VERSION "..\..\trunk\components\winTestMT\code\canApi\dbcFiles\canBus_03.dbc, created by Octave and generateRandomDbc.m on 21-Feb-2017"

NS_ :

BS_:

BU_: ECU

BO_ 1519 frame_1519: 4 Vector__XXX
  SG_ checksum_1_8 : 0|8@1+ (1.0,0.0) [0.0|255.0] "" ECU
  SG_ sig_14_12 : 14|12@1+ (1.0000000000000005E-4,0.31622776601683794) [0.31622776601683794|0.7256277660168382] "A" ECU
  SG_ sig_8_6 : 8|6@1- (1.0,0.0) [-32.0|30.0] "" ECU
  SG_ sig_27_5 : 27|5@1+ (1.0000000000000006E-5,3.1622776601683794E-4) [3.1622776601683794E-4|6.162277660168381E-4] "km/h" ECU
  SG_ sig_26_1 : 26|1@1+ (1.0,0.0) [0.0|1.0] "" ECU

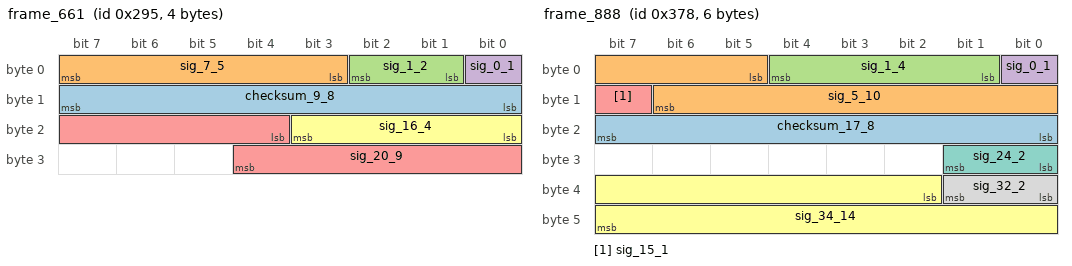
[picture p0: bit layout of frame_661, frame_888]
BO_ 661 frame_661: 4 ECU
  SG_ checksum_9_8 : 8|8@1+ (1.0,0.0) [0.0|255.0] "" Vector__XXX
  SG_ sig_7_5 : 7|5@0- (0.0010000000000000002,0.03162277660168379) [0.015622776601683788|0.0456227766016838] "km/h" Vector__XXX
  SG_ sig_1_2 : 1|2@1+ (1.0,0.0) [0.0|3.0] "" Vector__XXX
  SG_ sig_0_1 : 0|1@1+ (1.0,0.0) [0.0|1.0] "" Vector__XXX
  SG_ sig_20_9 : 20|9@1+ (1.0000000000000006E-6,3.1622776601683794E-4) [3.1622776601683794E-4|8.262277660168382E-4] "km/h" Vector__XXX
  SG_ sig_16_4 : 16|4@1+ (1.0,0.0) [0.0|14.0] "" Vector__XXX

BO_ 1084 frame_1084: 4 ECU
  SG_ checksum_1_8 : 0|8@1+ (1.0,0.0) [0.0|255.0] "" Vector__XXX
  SG_ sig_11_14 : 11|14@0+ (1.0000000000000009E-9,-3.162277660168379E-6) [-3.162277660168379E-6|1.3219722339831634E-5] "V" Vector__XXX
  SG_ sig_15_4 : 15|4@0- (1.0000000000000006E-5,-3.1622776601683795E-5) [-1.1162277660168384E-4|2.837722339831624E-5] "kWh" Vector__XXX

BO_ 888 frame_888: 6 Vector__XXX
  SG_ checksum_17_8 : 16|8@1+ (1.0,0.0) [0.0|255.0] "" ECU
  SG_ sig_5_10 : 5|10@1+ (1.0,0.0) [0.0|1022.0] "" ECU
  SG_ sig_1_4 : 1|4@1- (1.0,0.0) [-8.0|6.0] "" ECU
  SG_ sig_0_1 : 0|1@1+ (1.0,0.0) [0.0|1.0] "" ECU
  SG_ sig_15_1 : 15|1@1+ (1.0,0.0) [0.0|1.0] "" ECU
  SG_ sig_34_14 : 34|14@1- (1.0000000000000009E-9,-3.162277660168379E-6) [-1.1354277660168386E-5|5.027722339831629E-6] "A" ECU
  SG_ sig_24_2 : 24|2@1+ (1.0,0.0) [0.0|3.0] "" ECU
  SG_ sig_32_2 : 32|2@1+ (1.0,0.0) [0.0|3.0] "" ECU

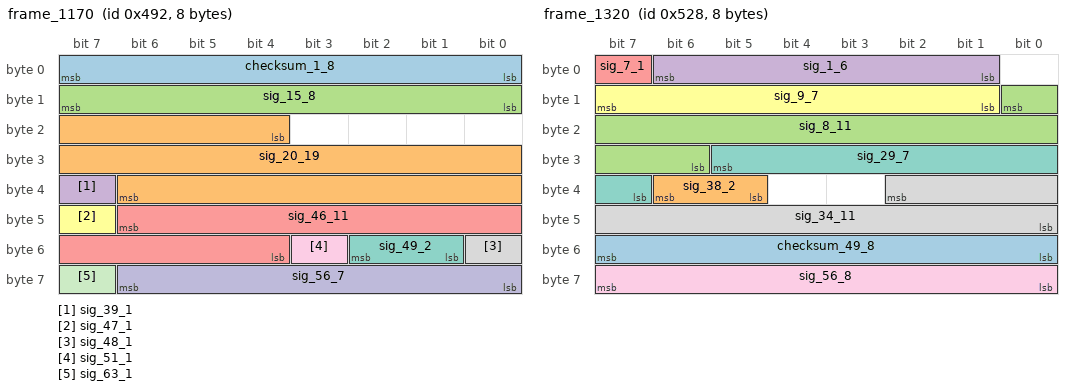
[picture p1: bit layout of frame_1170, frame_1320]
BO_ 1170 frame_1170: 8 ECU
  SG_ checksum_1_8 : 7|8@0+ (1.0,0.0) [0.0|255.0] "" Vector__XXX
  SG_ sig_20_19 : 20|19@1- (0.1,-31622.776601683792) [-57837.176601683794|-5408.5766016837915] "kWh" Vector__XXX
  SG_ sig_15_8 : 15|8@0+ (0.0010000000000000002,0.0) [0.0|0.25400000000000006] "V" Vector__XXX
  SG_ sig_39_1 : 39|1@0+ (1.0,0.0) [0.0|1.0] "" Vector__XXX
  SG_ sig_46_11 : 46|11@0+ (0.0010000000000000002,0.31622776601683794) [0.31622776601683794|2.3622277660168387] "V" Vector__XXX
  SG_ sig_47_1 : 47|1@0+ (1.0,0.0) [0.0|1.0] "" Vector__XXX
  SG_ sig_49_2 : 49|2@1- (1.0,0.0) [-2.0|1.0] "" Vector__XXX
  SG_ sig_48_1 : 48|1@1+ (1.0,0.0) [0.0|1.0] "" Vector__XXX
  SG_ sig_51_1 : 51|1@0+ (1.0,0.0) [0.0|1.0] "" Vector__XXX
  SG_ sig_56_7 : 56|7@1- (1.0000000000000007E-7,3.162277660168379E-6) [-3.2377223398316256E-6|9.362277660168384E-6] "km/h" Vector__XXX
  SG_ sig_63_1 : 63|1@1+ (1.0,0.0) [0.0|1.0] "" Vector__XXX

BO_ 1320 frame_1320: 8 Vector__XXX
  SG_ checksum_49_8 : 48|8@1+ (1.0,0.0) [0.0|255.0] "" ECU
  SG_ sig_38_2 : 38|2@0- (1.0,0.0) [-2.0|1.0] "" ECU
  SG_ sig_8_11 : 8|11@0+ (1.0,0.0) [0.0|2046.0] "" ECU
  SG_ sig_1_6 : 1|6@1- (1.0,0.0) [-32.0|30.0] "" ECU
  SG_ sig_7_1 : 7|1@0+ (1.0,0.0) [0.0|1.0] "" ECU
  SG_ sig_9_7 : 9|7@1- (0.010000000000000002,-0.31622776601683794) [-0.9562277660168381|0.30377223398316217] "s" ECU
  SG_ sig_29_7 : 29|7@0+ (10.0,0.0) [0.0|1260.0] "W" ECU
  SG_ sig_34_11 : 34|11@0+ (1.0,0.0) [0.0|2046.0] "" ECU
  SG_ sig_56_8 : 56|8@1+ (100.0,3162.2776601683795) [3162.2776601683795|28562.27766016838] "m/s^2" ECU

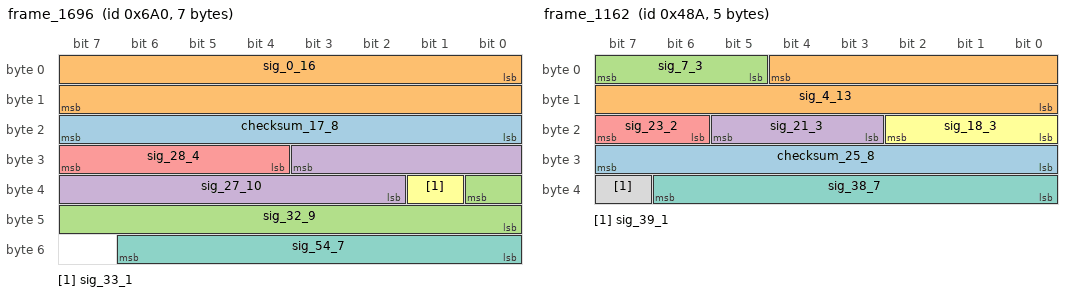
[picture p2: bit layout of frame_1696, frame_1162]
BO_ 1696 frame_1696: 7 ECU
  SG_ checksum_17_8 : 16|8@1+ (1.0,0.0) [0.0|255.0] "" Vector__XXX
  SG_ sig_0_16 : 0|16@1+ (1.0000000000000009E-9,3.1622776601683795E-5) [3.1622776601683795E-5|9.715677660168386E-5] "s" Vector__XXX
  SG_ sig_32_9 : 32|9@0- (1.0,0.0) [-256.0|254.0] "" Vector__XXX
  SG_ sig_27_10 : 27|10@0- (0.1,31.622776601683793) [-19.57722339831621|82.6227766016838] "kWh" Vector__XXX
  SG_ sig_28_4 : 28|4@1- (1.0,0.0) [-8.0|6.0] "" Vector__XXX
  SG_ sig_33_1 : 33|1@1+ (1.0,0.0) [0.0|1.0] "" Vector__XXX
  SG_ sig_54_7 : 54|7@0- (1.0000000000000006E-5,3.1622776601683794E-4) [-3.2377223398316244E-4|9.362277660168383E-4] "A" Vector__XXX

BO_ 1162 frame_1162: 5 Vector__XXX
  SG_ checksum_25_8 : 31|8@0+ (1.0,0.0) [0.0|255.0] "" ECU
  SG_ sig_4_13 : 4|13@0- (1.0000000000000005E-4,0.31622776601683794) [-0.09337223398316224|0.7256277660168382] "V" ECU
  SG_ sig_7_3 : 7|3@0- (1.0,0.0) [-4.0|2.0] "" ECU
  SG_ sig_21_3 : 21|3@0+ (1.0,0.0) [0.0|6.0] "" ECU
  SG_ sig_23_2 : 23|2@0- (1.0,0.0) [-2.0|1.0] "" ECU
  SG_ sig_18_3 : 18|3@0- (1.0,0.0) [-4.0|2.0] "" ECU
  SG_ sig_38_7 : 38|7@0+ (10.0,-316.22776601683796) [-316.22776601683796|943.7722339831621] "kWh" ECU
  SG_ sig_39_1 : 39|1@0+ (1.0,0.0) [0.0|1.0] "" ECU

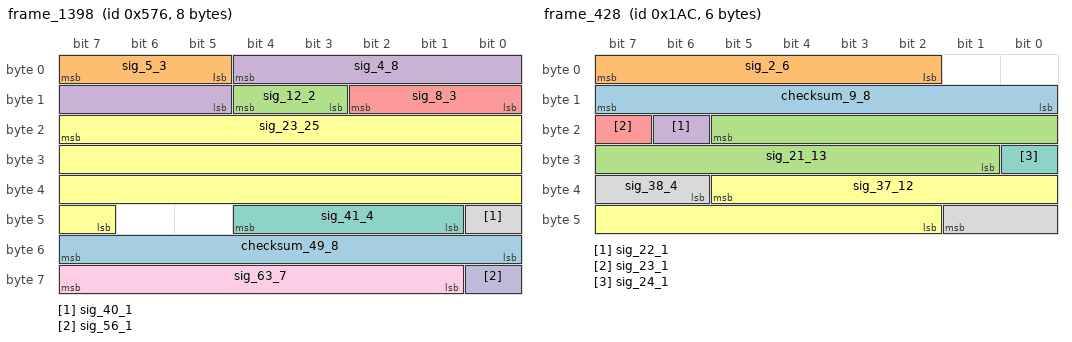
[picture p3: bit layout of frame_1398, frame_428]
BO_ 1398 frame_1398: 8 ECU
  SG_ checksum_49_8 : 55|8@0+ (1.0,0.0) [0.0|255.0] "" Vector__XXX
  SG_ sig_5_3 : 5|3@1- (1.0,0.0) [-4.0|2.0] "" Vector__XXX
  SG_ sig_12_2 : 12|2@0- (1.0,0.0) [-2.0|1.0] "" Vector__XXX
  SG_ sig_4_8 : 4|8@0- (1.0000000000000006E-6,-3.1622776601683795E-5) [-1.5962277660168386E-4|9.437722339831629E-5] "W" Vector__XXX
  SG_ sig_8_3 : 8|3@1- (1.0,0.0) [-4.0|2.0] "" Vector__XXX
  SG_ sig_23_25 : 23|25@0+ (1.0000000000000006E-5,316.22776601683796) [316.22776601683796|651.7720660168382] "km/h" Vector__XXX
  SG_ sig_41_4 : 41|4@1+ (1.0,0.0) [0.0|14.0] "" Vector__XXX
  SG_ sig_40_1 : 40|1@1+ (1.0,0.0) [0.0|1.0] "" Vector__XXX
  SG_ sig_63_7 : 63|7@0+ (1.0,0.0) [0.0|126.0] "" Vector__XXX
  SG_ sig_56_1 : 56|1@0+ (1.0,0.0) [0.0|1.0] "" Vector__XXX

BO_ 187 frame_187: 4 Vector__XXX
  SG_ checksum_1_8 : 0|8@1+ (1.0,0.0) [0.0|255.0] "" ECU
  SG_ sig_13_16 : 13|16@0+ (1.0,0.0) [0.0|65534.0] "" ECU
  SG_ sig_15_2 : 15|2@0- (1.0,0.0) [-2.0|1.0] "" ECU
  SG_ sig_28_5 : 28|5@0+ (1.0,0.0) [0.0|30.0] "" ECU

BO_ 428 frame_428: 6 Vector__XXX
  SG_ checksum_9_8 : 15|8@0+ (1.0,0.0) [0.0|255.0] "" ECU
  SG_ sig_2_6 : 2|6@1+ (0.010000000000000002,-0.31622776601683794) [-0.31622776601683794|0.30377223398316217] "A" ECU
  SG_ sig_21_13 : 21|13@0- (1.0,0.0) [-4096.0|4094.0] "" ECU
  SG_ sig_22_1 : 22|1@0+ (1.0,0.0) [0.0|1.0] "" ECU
  SG_ sig_23_1 : 23|1@0+ (1.0,0.0) [0.0|1.0] "" ECU
  SG_ sig_37_12 : 37|12@0- (0.1,316.22776601683796) [111.42776601683795|520.827766016838] "kWh" ECU
  SG_ sig_24_1 : 24|1@1+ (1.0,0.0) [0.0|1.0] "" ECU
  SG_ sig_38_4 : 38|4@1+ (0.0010000000000000002,0.0) [0.0|0.014000000000000004] "A" ECU

BO_ 1425 frame_1425: 5 ECU
  SG_ checksum_25_8 : 24|8@1+ (1.0,0.0) [0.0|255.0] "" Vector__XXX
  SG_ sig_7_16 : 7|16@1+ (1.0,0.0) [0.0|65534.0] "" Vector__XXX
  SG_ sig_6_7 : 6|7@0+ (1.0,0.0) [0.0|126.0] "" Vector__XXX
  SG_ sig_23_1 : 23|1@0+ (1.0,0.0) [0.0|1.0] "" Vector__XXX
  SG_ sig_39_8 : 39|8@0- (1.0,0.0) [-128.0|126.0] "" Vector__XXX

BO_ 1217 frame_1217: 3 Vector__XXX
  SG_ checksum_17_8 : 23|8@0+ (1.0,0.0) [0.0|255.0] "" ECU
  SG_ sig_4_10 : 4|10@0- (1.0,0.0) [-512.0|510.0] "" ECU
  SG_ sig_7_2 : 7|2@0+ (1.0,0.0) [0.0|3.0] "" ECU
  SG_ sig_5_1 : 5|1@0+ (1.0,0.0) [0.0|1.0] "" ECU
  SG_ sig_10_3 : 10|3@0+ (1.0,0.0) [0.0|6.0] "" ECU

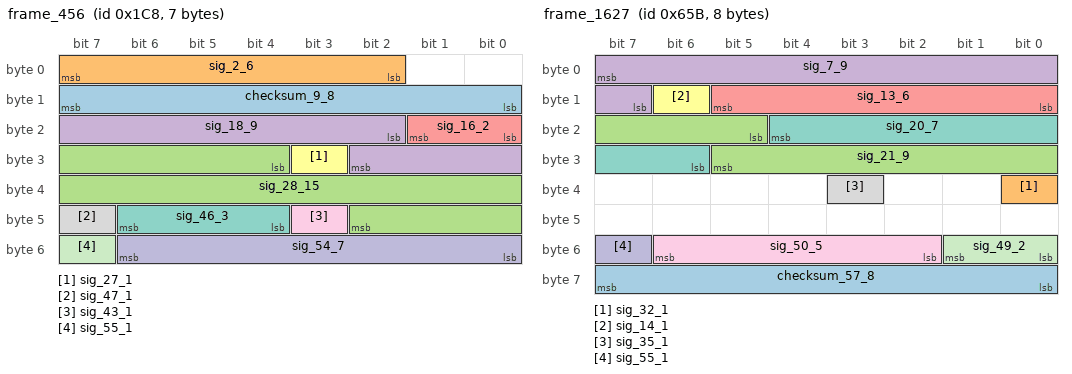
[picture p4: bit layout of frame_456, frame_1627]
BO_ 456 frame_456: 7 Vector__XXX
  SG_ checksum_9_8 : 8|8@1+ (1.0,0.0) [0.0|255.0] "" ECU
  SG_ sig_2_6 : 2|6@1+ (0.1,3.1622776601683795) [3.1622776601683795|9.36227766016838] "km/h" ECU
  SG_ sig_28_15 : 28|15@1- (0.1,3162.2776601683795) [1523.8776601683794|4800.47766016838] "V" ECU
  SG_ sig_18_9 : 18|9@1- (0.010000000000000002,0.0) [-2.5600000000000005|2.5400000000000005] "kWh" ECU
  SG_ sig_16_2 : 16|2@1+ (1.0,0.0) [0.0|3.0] "" ECU
  SG_ sig_27_1 : 27|1@1+ (1.0,0.0) [0.0|1.0] "" ECU
  SG_ sig_46_3 : 46|3@0- (1.0,0.0) [-4.0|2.0] "" ECU
  SG_ sig_47_1 : 47|1@0+ (1.0,0.0) [0.0|1.0] "" ECU
  SG_ sig_43_1 : 43|1@1+ (1.0,0.0) [0.0|1.0] "" ECU
  SG_ sig_54_7 : 54|7@0- (1.0,0.0) [-64.0|62.0] "" ECU
  SG_ sig_55_1 : 55|1@0+ (1.0,0.0) [0.0|1.0] "" ECU

BO_ 1627 frame_1627: 8 Vector__XXX
  SG_ checksum_57_8 : 56|8@1+ (1.0,0.0) [0.0|255.0] "" ECU
  SG_ sig_32_1 : 32|1@0+ (1.0,0.0) [0.0|1.0] "" ECU
  SG_ sig_21_9 : 21|9@1- (0.1,31.622776601683793) [6.022776601683791|57.022776601683795] "km/h" ECU
  SG_ sig_7_9 : 7|9@0- (0.010000000000000002,0.0) [-2.5600000000000005|2.5400000000000005] "m/s^2" ECU
  SG_ sig_13_6 : 13|6@0+ (1.0,0.0) [0.0|62.0] "" ECU
  SG_ sig_14_1 : 14|1@1+ (1.0,0.0) [0.0|1.0] "" ECU
  SG_ sig_20_7 : 20|7@0+ (1000.0,0.0) [0.0|126000.0] "kWh" ECU
  SG_ sig_35_1 : 35|1@1+ (1.0,0.0) [0.0|1.0] "" ECU
  SG_ sig_50_5 : 50|5@1+ (1.0000000000000005E-4,0.0) [0.0|0.0030000000000000014] "km/h" ECU
  SG_ sig_55_1 : 55|1@0+ (1.0,0.0) [0.0|1.0] "" ECU
  SG_ sig_49_2 : 49|2@0+ (1.0,0.0) [0.0|3.0] "" ECU

BO_ 804 frame_804: 7 Vector__XXX
  SG_ checksum_9_8 : 15|8@0+ (1.0,0.0) [0.0|255.0] "" ECU
  SG_ sig_7_7 : 7|7@0+ (0.0010000000000000002,0.03162277660168379) [0.03162277660168379|0.15762277660168383] "km/h" ECU
  SG_ sig_0_1 : 0|1@0+ (1.0,0.0) [0.0|1.0] "" ECU
  SG_ sig_22_19 : 22|19@0- (1.0000000000000011E-10,0.0) [-2.6214400000000028E-5|2.6214200000000028E-5] "kWh" ECU
  SG_ sig_34_19 : 34|19@0- (1.000000000000001E-11,-3.162277660168379E-6) [-5.783717660168382E-6|-5.408576601683765E-7] "V" ECU
  SG_ sig_35_1 : 35|1@0+ (1.0,0.0) [0.0|1.0] "" ECU

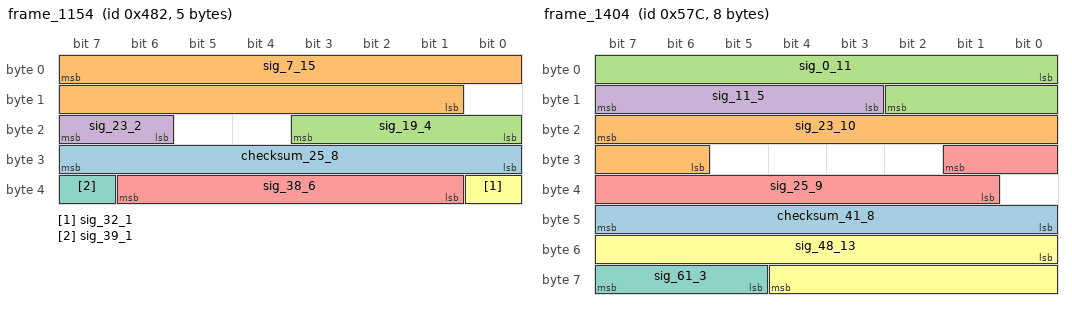
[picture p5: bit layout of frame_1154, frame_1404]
BO_ 1154 frame_1154: 5 ECU
  SG_ checksum_25_8 : 31|8@0+ (1.0,0.0) [0.0|255.0] "" Vector__XXX
  SG_ sig_7_15 : 7|15@0+ (0.1,-3162.2776601683795) [-3162.2776601683795|114.32233983162087] "m/s^2" Vector__XXX
  SG_ sig_19_4 : 19|4@0- (1.0000000000000006E-5,0.0) [-8.000000000000005E-5|6.0000000000000035E-5] "km/h" Vector__XXX
  SG_ sig_23_2 : 23|2@0+ (1.0,0.0) [0.0|3.0] "" Vector__XXX
  SG_ sig_38_6 : 38|6@0- (1.0,0.0) [-32.0|30.0] "" Vector__XXX
  SG_ sig_32_1 : 32|1@1+ (1.0,0.0) [0.0|1.0] "" Vector__XXX
  SG_ sig_39_1 : 39|1@0+ (1.0,0.0) [0.0|1.0] "" Vector__XXX

BO_ 1404 frame_1404: 8 ECU
  SG_ checksum_41_8 : 47|8@0+ (1.0,0.0) [0.0|255.0] "" Vector__XXX
  SG_ sig_23_10 : 23|10@0+ (1.0000000000000005E-4,0.0) [0.0|0.10220000000000004] "kWh" Vector__XXX
  SG_ sig_0_11 : 0|11@1+ (1.0,0.0) [0.0|2046.0] "" Vector__XXX
  SG_ sig_11_5 : 11|5@1+ (100.0,3162.2776601683795) [3162.2776601683795|6162.27766016838] "W" Vector__XXX
  SG_ sig_25_9 : 25|9@0- (0.010000000000000002,3.1622776601683795) [0.602277660168379|5.70227766016838] "m/s^2" Vector__XXX
  SG_ sig_48_13 : 48|13@1+ (1.0000000000000006E-5,0.0) [0.0|0.08190000000000004] "W" Vector__XXX
  SG_ sig_61_3 : 61|3@1+ (1.0,0.0) [0.0|6.0] "" Vector__XXX

BO_ 259 frame_259: 4 Vector__XXX
  SG_ checksum_1_8 : 0|8@1+ (1.0,0.0) [0.0|255.0] "" ECU
  SG_ sig_13_17 : 13|17@1- (1.0000000000000006E-6,0.03162277660168379) [-0.03391322339831625|0.09715677660168383] "V" ECU
  SG_ sig_11_4 : 11|4@0- (100.0,316.22776601683796) [-483.77223398316204|916.2277660168379] "m/s^2" ECU

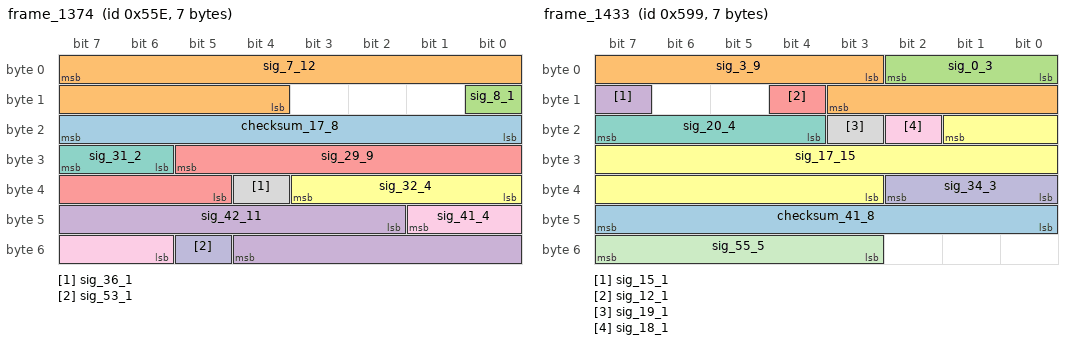
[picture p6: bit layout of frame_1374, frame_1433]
BO_ 1374 frame_1374: 7 ECU
  SG_ checksum_17_8 : 23|8@0+ (1.0,0.0) [0.0|255.0] "" Vector__XXX
  SG_ sig_7_12 : 7|12@0+ (1.0,0.0) [0.0|4094.0] "" Vector__XXX
  SG_ sig_8_1 : 8|1@1+ (1.0,0.0) [0.0|1.0] "" Vector__XXX
  SG_ sig_42_11 : 42|11@1- (1.0000000000000006E-6,3.1622776601683794E-4) [-7.077722339831627E-4|0.0013382277660168385] "kWh" Vector__XXX
  SG_ sig_29_9 : 29|9@0- (0.0010000000000000002,0.31622776601683794) [0.06022776601683788|0.570227766016838] "s" Vector__XXX
  SG_ sig_32_4 : 32|4@1- (1.0,0.0) [-8.0|6.0] "" Vector__XXX
  SG_ sig_31_2 : 31|2@0- (1.0,0.0) [-2.0|1.0] "" Vector__XXX
  SG_ sig_36_1 : 36|1@1+ (1.0,0.0) [0.0|1.0] "" Vector__XXX
  SG_ sig_41_4 : 41|4@0+ (0.0010000000000000002,-0.0031622776601683794) [-0.0031622776601683794|0.010837722339831624] "s" Vector__XXX
  SG_ sig_53_1 : 53|1@1+ (1.0,0.0) [0.0|1.0] "" Vector__XXX

BO_ 820 frame_820: 4 ECU
  SG_ checksum_25_8 : 31|8@0+ (1.0,0.0) [0.0|255.0] "" Vector__XXX
  SG_ sig_0_14 : 0|14@1- (1.0000000000000009E-9,3.162277660168379E-6) [-5.029722339831628E-6|1.1352277660168387E-5] "kWh" Vector__XXX
  SG_ sig_17_5 : 17|5@1+ (1.0,-31.622776601683793) [-31.622776601683793|-1.6227766016837926] "V" Vector__XXX
  SG_ sig_23_1 : 23|1@0+ (1.0,0.0) [0.0|1.0] "" Vector__XXX
  SG_ sig_22_1 : 22|1@0+ (1.0,0.0) [0.0|1.0] "" Vector__XXX
  SG_ sig_16_1 : 16|1@0+ (1.0,0.0) [0.0|1.0] "" Vector__XXX

BO_ 1433 frame_1433: 7 Vector__XXX
  SG_ checksum_41_8 : 40|8@1+ (1.0,0.0) [0.0|255.0] "" ECU
  SG_ sig_3_9 : 3|9@1+ (1.0,0.0) [0.0|510.0] "" ECU
  SG_ sig_0_3 : 0|3@1+ (1.0,0.0) [0.0|6.0] "" ECU
  SG_ sig_15_1 : 15|1@0+ (1.0,0.0) [0.0|1.0] "" ECU
  SG_ sig_12_1 : 12|1@1+ (1.0,0.0) [0.0|1.0] "" ECU
  SG_ sig_17_15 : 17|15@0+ (1.0000000000000006E-6,0.03162277660168379) [0.03162277660168379|0.06438877660168381] "kWh" ECU
  SG_ sig_20_4 : 20|4@1- (10000.0,0.0) [-80000.0|60000.0] "s" ECU
  SG_ sig_19_1 : 19|1@0+ (1.0,0.0) [0.0|1.0] "" ECU
  SG_ sig_18_1 : 18|1@1+ (1.0,0.0) [0.0|1.0] "" ECU
  SG_ sig_34_3 : 34|3@0+ (1.0,0.0) [0.0|6.0] "" ECU
  SG_ sig_55_5 : 55|5@0- (100.0,3162.2776601683795) [1562.2776601683795|4562.27766016838] "m/s^2" ECU

BO_ 1820 frame_1820: 4 Vector__XXX
  SG_ checksum_25_8 : 31|8@0+ (1.0,0.0) [0.0|255.0] "" ECU
  SG_ sig_2_16 : 2|16@0+ (1.0,0.0) [0.0|65534.0] "" ECU
  SG_ sig_7_4 : 7|4@0- (10.0,0.0) [-80.0|60.0] "kWh" ECU
  SG_ sig_17_2 : 17|2@1+ (1.0,0.0) [0.0|3.0] "" ECU

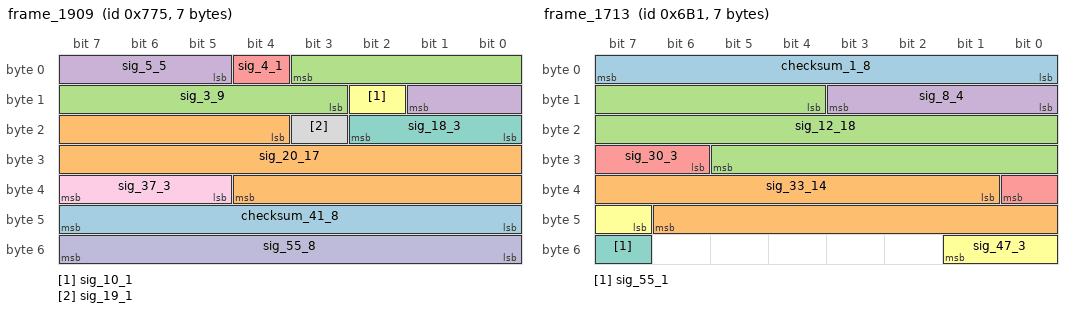
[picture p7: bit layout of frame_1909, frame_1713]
BO_ 1909 frame_1909: 7 Vector__XXX
  SG_ checksum_41_8 : 47|8@0+ (1.0,0.0) [0.0|255.0] "" ECU
  SG_ sig_20_17 : 20|17@1- (1.0,0.0) [-65536.0|65534.0] "" ECU
  SG_ sig_3_9 : 3|9@0+ (0.1,-31.622776601683793) [-31.622776601683793|19.377223398316207] "s" ECU
  SG_ sig_5_5 : 5|5@1+ (1.0,0.0) [0.0|30.0] "" ECU
  SG_ sig_4_1 : 4|1@0+ (1.0,0.0) [0.0|1.0] "" ECU
  SG_ sig_10_1 : 10|1@0+ (1.0,0.0) [0.0|1.0] "" ECU
  SG_ sig_18_3 : 18|3@0+ (1.0,0.0) [0.0|6.0] "" ECU
  SG_ sig_19_1 : 19|1@0+ (1.0,0.0) [0.0|1.0] "" ECU
  SG_ sig_37_3 : 37|3@1+ (1.0,0.0) [0.0|6.0] "" ECU
  SG_ sig_55_8 : 55|8@0- (10.0,316.22776601683796) [-963.7722339831621|1576.227766016838] "km/h" ECU

BO_ 1713 frame_1713: 7 ECU
  SG_ checksum_1_8 : 0|8@1+ (1.0,0.0) [0.0|255.0] "" Vector__XXX
  SG_ sig_33_14 : 33|14@1+ (1.0,0.0) [0.0|16382.0] "" Vector__XXX
  SG_ sig_12_18 : 12|18@1+ (1.0,0.0) [0.0|262142.0] "" Vector__XXX
  SG_ sig_8_4 : 8|4@1+ (1.0000000000000005E-4,-3.1622776601683794E-4) [-3.1622776601683794E-4|0.0010837722339831627] "kWh" Vector__XXX
  SG_ sig_30_3 : 30|3@1- (1.0,0.0) [-4.0|2.0] "" Vector__XXX
  SG_ sig_47_3 : 47|3@1+ (1.0,0.0) [0.0|6.0] "" Vector__XXX
  SG_ sig_55_1 : 55|1@0+ (1.0,0.0) [0.0|1.0] "" Vector__XXX

BO_ 1318 frame_1318: 5 Vector__XXX
  SG_ checksum_9_8 : 15|8@0+ (1.0,0.0) [0.0|255.0] "" ECU
  SG_ sig_5_5 : 5|5@0- (10.0,0.0) [-160.0|140.0] "W" ECU
  SG_ sig_7_2 : 7|2@0- (1.0,0.0) [-2.0|1.0] "" ECU
  SG_ sig_31_16 : 31|16@0+ (0.1,0.0) [0.0|6553.400000000001] "s" ECU
  SG_ sig_22_7 : 22|7@0- (1.0,0.0) [-64.0|62.0] "" ECU
  SG_ sig_23_1 : 23|1@0+ (1.0,0.0) [0.0|1.0] "" ECU

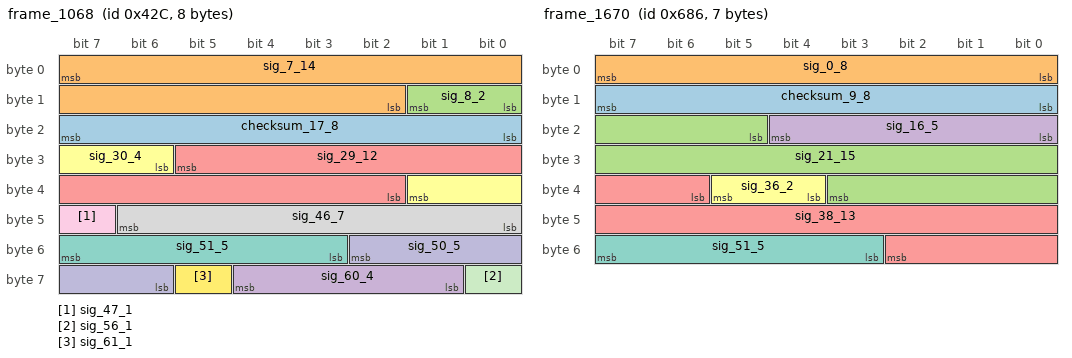
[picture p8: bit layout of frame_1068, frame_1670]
BO_ 1068 frame_1068: 8 Vector__XXX
  SG_ checksum_17_8 : 23|8@0+ (1.0,0.0) [0.0|255.0] "" ECU
  SG_ sig_7_14 : 7|14@0- (1.0000000000000005E-4,-0.31622776601683794) [-1.1354277660168384|0.5027722339831624] "s" ECU
  SG_ sig_8_2 : 8|2@1- (1.0,0.0) [-2.0|1.0] "" ECU
  SG_ sig_60_4 : 60|4@0+ (0.0010000000000000002,-0.0031622776601683794) [-0.0031622776601683794|0.010837722339831624] "km/h" ECU
  SG_ sig_29_12 : 29|12@0+ (1.0000000000000006E-6,0.0031622776601683794) [0.0031622776601683794|0.007256277660168382] "s" ECU
  SG_ sig_30_4 : 30|4@1- (1.0,0.0) [-8.0|6.0] "" ECU
  SG_ sig_51_5 : 51|5@1+ (1000.0,0.0) [0.0|30000.0] "V" ECU
  SG_ sig_46_7 : 46|7@0+ (1.0000000000000006E-6,3.1622776601683795E-5) [3.1622776601683795E-5|1.5762277660168387E-4] "km/h" ECU
  SG_ sig_47_1 : 47|1@0+ (1.0,0.0) [0.0|1.0] "" ECU
  SG_ sig_50_5 : 50|5@0- (0.1,0.0) [-1.6|1.4000000000000001] "m/s^2" ECU
  SG_ sig_56_1 : 56|1@1+ (1.0,0.0) [0.0|1.0] "" ECU
  SG_ sig_61_1 : 61|1@1+ (1.0,0.0) [0.0|1.0] "" ECU

BO_ 1670 frame_1670: 7 Vector__XXX
  SG_ checksum_9_8 : 8|8@1+ (1.0,0.0) [0.0|255.0] "" ECU
  SG_ sig_0_8 : 0|8@1- (1000.0,0.0) [-128000.0|126000.0] "s" ECU
  SG_ sig_21_15 : 21|15@1+ (1.0,0.0) [0.0|32766.0] "" ECU
  SG_ sig_16_5 : 16|5@1+ (0.1,-3.1622776601683795) [-3.1622776601683795|-0.16227766016837952] "W" ECU
  SG_ sig_38_13 : 38|13@1+ (1.0,-3162.2776601683795) [-3162.2776601683795|5027.72233983162] "kWh" ECU
  SG_ sig_36_2 : 36|2@1- (1.0,0.0) [-2.0|1.0] "" ECU
  SG_ sig_51_5 : 51|5@1+ (1.0,0.0) [0.0|30.0] "" ECU

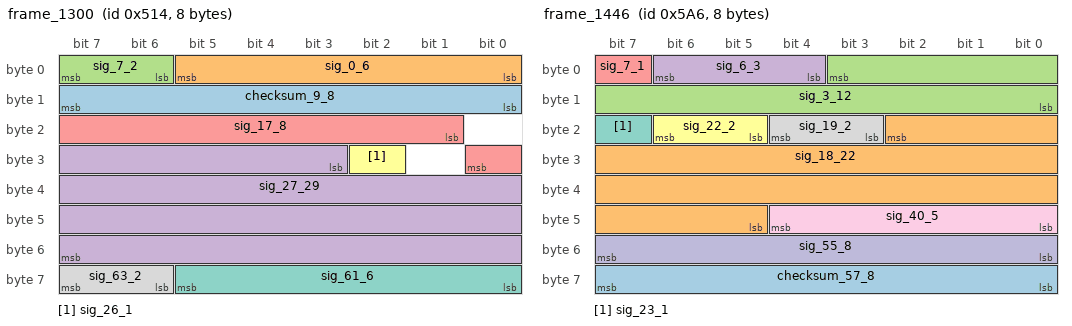
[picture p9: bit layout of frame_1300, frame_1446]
BO_ 1300 frame_1300: 8 Vector__XXX
  SG_ checksum_9_8 : 15|8@0+ (1.0,0.0) [0.0|255.0] "" ECU
  SG_ sig_0_6 : 0|6@1- (1000.0,-31622.776601683792) [-63622.77660168379|-1622.7766016837923] "s" ECU
  SG_ sig_7_2 : 7|2@0- (1.0,0.0) [-2.0|1.0] "" ECU
  SG_ sig_27_29 : 27|29@1- (1.0000000000000011E-10,-0.03162277660168379) [-0.058466322201683824|-0.004779231201683762] "A" ECU
  SG_ sig_17_8 : 17|8@1+ (0.1,3.1622776601683795) [3.1622776601683795|28.56227766016838] "W" ECU
  SG_ sig_26_1 : 26|1@0+ (1.0,0.0) [0.0|1.0] "" ECU
  SG_ sig_61_6 : 61|6@0- (1.0000000000000005E-4,-0.0031622776601683794) [-0.006362277660168381|-1.6227766016837803E-4] "m/s^2" ECU
  SG_ sig_63_2 : 63|2@0- (1.0,0.0) [-2.0|1.0] "" ECU

BO_ 1446 frame_1446: 8 Vector__XXX
  SG_ checksum_57_8 : 63|8@0+ (1.0,0.0) [0.0|255.0] "" ECU
  SG_ sig_18_22 : 18|22@0- (1.0000000000000007E-7,-0.31622776601683794) [-0.5259429660168381|-0.10651276601683779] "W" ECU
  SG_ sig_3_12 : 3|12@0- (1.0000000000000007E-7,-3.1622776601683794E-4) [-5.210277660168381E-4|-1.1162776601683779E-4] "A" ECU
  SG_ sig_6_3 : 6|3@0+ (1.0,0.0) [0.0|6.0] "" ECU
  SG_ sig_7_1 : 7|1@1+ (1.0,0.0) [0.0|1.0] "" ECU
  SG_ sig_22_2 : 22|2@0+ (1.0,0.0) [0.0|3.0] "" ECU
  SG_ sig_23_1 : 23|1@0+ (1.0,0.0) [0.0|1.0] "" ECU
  SG_ sig_19_2 : 19|2@1+ (1.0,0.0) [0.0|3.0] "" ECU
  SG_ sig_40_5 : 40|5@1+ (1.0,0.0) [0.0|30.0] "" ECU
  SG_ sig_55_8 : 55|8@0+ (0.010000000000000002,0.0) [0.0|2.5400000000000005] "km/h" ECU

BO_ 144 frame_144: 6 Vector__XXX
  SG_ checksum_25_8 : 24|8@1+ (1.0,0.0) [0.0|255.0] "" ECU
  SG_ sig_3_17 : 3|17@1- (1.0000000000000005E-4,3.1622776601683795) [-3.3913223398316235|9.715677660168382] "V" ECU
  SG_ sig_0_3 : 0|3@1+ (1.0,0.0) [0.0|6.0] "" ECU
  SG_ sig_20_4 : 20|4@1- (1.0,-3.1622776601683795) [-11.16227766016838|2.8377223398316205] "s" ECU
  SG_ sig_32_11 : 32|11@1+ (1.0000000000000008E-8,3.162277660168379E-6) [3.162277660168379E-6|2.3622277660168395E-5] "s" ECU
  SG_ sig_43_5 : 43|5@1+ (1.0,0.0) [0.0|30.0] "" ECU

BO_ 1029 frame_1029: 7 Vector__XXX
  SG_ checksum_9_8 : 15|8@0+ (1.0,0.0) [0.0|255.0] "" ECU
  SG_ sig_7_6 : 7|6@0- (1.0,0.0) [-32.0|30.0] "" ECU
  SG_ sig_1_2 : 1|2@0- (1.0,0.0) [-2.0|1.0] "" ECU
  SG_ sig_16_33 : 16|33@1+ (1.000000000000001E-11,0.03162277660168379) [0.03162277660168379|0.11752212250168388] "V" ECU
  SG_ sig_50_2 : 50|2@0+ (1.0,0.0) [0.0|3.0] "" ECU

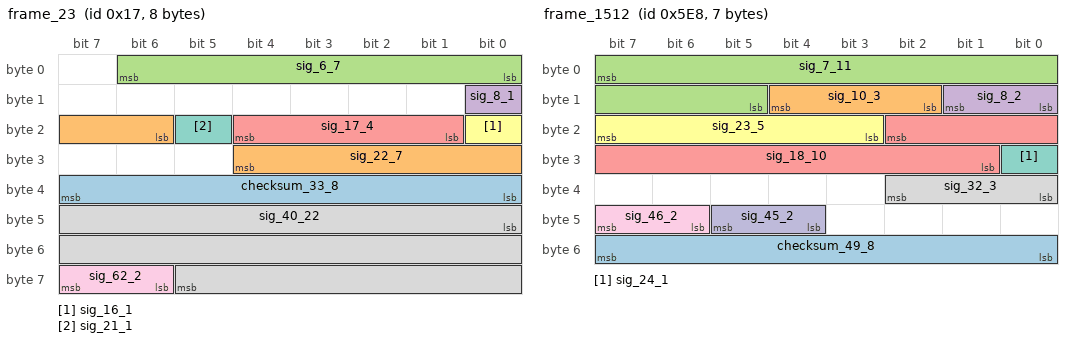
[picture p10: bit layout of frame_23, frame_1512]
BO_ 23 frame_23: 8 Vector__XXX
  SG_ checksum_33_8 : 32|8@1+ (1.0,0.0) [0.0|255.0] "" ECU
  SG_ sig_22_7 : 22|7@1- (0.010000000000000002,0.31622776601683794) [-0.3237722339831622|0.9362277660168381] "km/h" ECU
  SG_ sig_6_7 : 6|7@0+ (0.1,-3.1622776601683795) [-3.1622776601683795|9.437722339831621] "s" ECU
  SG_ sig_8_1 : 8|1@1+ (1.0,0.0) [0.0|1.0] "" ECU
  SG_ sig_17_4 : 17|4@1- (0.010000000000000002,0.0) [-0.08000000000000002|0.06000000000000001] "W" ECU
  SG_ sig_16_1 : 16|1@1+ (1.0,0.0) [0.0|1.0] "" ECU
  SG_ sig_21_1 : 21|1@0+ (1.0,0.0) [0.0|1.0] "" ECU
  SG_ sig_40_22 : 40|22@1- (1.0000000000000005E-4,0.0) [-209.7152000000001|209.7150000000001] "km/h" ECU
  SG_ sig_62_2 : 62|2@1+ (1.0,0.0) [0.0|3.0] "" ECU

BO_ 1485 frame_1485: 7 ECU
  SG_ checksum_49_8 : 55|8@0+ (1.0,0.0) [0.0|255.0] "" Vector__XXX
  SG_ sig_11_20 : 11|20@0+ (1.0000000000000005E-4,-31.622776601683793) [-31.622776601683793|73.23462339831624] "m/s^2" Vector__XXX
  SG_ sig_7_12 : 7|12@0- (10.0,-31622.776601683792) [-52102.77660168379|-11162.776601683792] "V" Vector__XXX
  SG_ sig_39_11 : 39|11@0- (1.0000000000000006E-5,0.0) [-0.010240000000000006|0.010220000000000007] "kWh" Vector__XXX
  SG_ sig_42_3 : 42|3@0- (1.0,0.0) [-4.0|2.0] "" Vector__XXX
  SG_ sig_44_2 : 44|2@0+ (1.0,0.0) [0.0|3.0] "" Vector__XXX

BO_ 1262 frame_1262: 5 Vector__XXX
  SG_ checksum_33_8 : 32|8@1+ (1.0,0.0) [0.0|255.0] "" ECU
  SG_ sig_7_21 : 7|21@1- (1.0000000000000011E-10,3.1622776601683795E-5) [-7.323482339831631E-5|1.364801766016839E-4] "A" ECU
  SG_ sig_6_7 : 6|7@0+ (1.0,0.0) [0.0|126.0] "" ECU
  SG_ sig_31_4 : 31|4@0- (0.010000000000000002,0.03162277660168379) [-0.048377223398316224|0.0916227766016838] "W" ECU

BO_ 1512 frame_1512: 7 Vector__XXX
  SG_ checksum_49_8 : 48|8@1+ (1.0,0.0) [0.0|255.0] "" ECU
  SG_ sig_10_3 : 10|3@1- (1.0,0.0) [-4.0|2.0] "" ECU
  SG_ sig_7_11 : 7|11@0+ (1.0,0.0) [0.0|2046.0] "" ECU
  SG_ sig_8_2 : 8|2@1+ (1.0,0.0) [0.0|3.0] "" ECU
  SG_ sig_18_10 : 18|10@0+ (0.1,-31.622776601683793) [-31.622776601683793|70.5772233983162] "V" ECU
  SG_ sig_23_5 : 23|5@0+ (1.0000000000000006E-5,0.0) [0.0|3.000000000000002E-4] "kWh" ECU
  SG_ sig_24_1 : 24|1@1+ (1.0,0.0) [0.0|1.0] "" ECU
  SG_ sig_32_3 : 32|3@1+ (1.0,0.0) [0.0|6.0] "" ECU
  SG_ sig_46_2 : 46|2@1- (1.0,0.0) [-2.0|1.0] "" ECU
  SG_ sig_45_2 : 45|2@0+ (1.0,0.0) [0.0|3.0] "" ECU

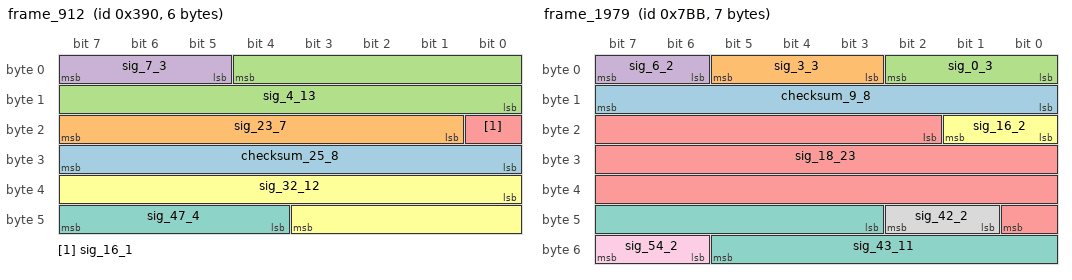
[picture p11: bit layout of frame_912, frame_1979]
BO_ 912 frame_912: 6 Vector__XXX
  SG_ checksum_25_8 : 24|8@1+ (1.0,0.0) [0.0|255.0] "" ECU
  SG_ sig_23_7 : 23|7@0+ (1.0,-31.622776601683793) [-31.622776601683793|94.3772233983162] "m/s^2" ECU
  SG_ sig_4_13 : 4|13@0+ (1.0000000000000006E-5,-0.03162277660168379) [-0.03162277660168379|0.05027722339831625] "kWh" ECU
  SG_ sig_7_3 : 7|3@0+ (1.0,0.0) [0.0|6.0] "" ECU
  SG_ sig_16_1 : 16|1@0+ (1.0,0.0) [0.0|1.0] "" ECU
  SG_ sig_32_12 : 32|12@1+ (1.0000000000000009E-9,0.0) [0.0|4.0940000000000035E-6] "W" ECU
  SG_ sig_47_4 : 47|4@0+ (1.0,0.0) [0.0|14.0] "" ECU

BO_ 1979 frame_1979: 7 Vector__XXX
  SG_ checksum_9_8 : 8|8@1+ (1.0,0.0) [0.0|255.0] "" ECU
  SG_ sig_3_3 : 3|3@1+ (1.0,0.0) [0.0|6.0] "" ECU
  SG_ sig_0_3 : 0|3@1+ (1.0,0.0) [0.0|6.0] "" ECU
  SG_ sig_6_2 : 6|2@1- (1.0,0.0) [-2.0|1.0] "" ECU
  SG_ sig_18_23 : 18|23@1+ (1.0000000000000009E-9,-0.0031622776601683794) [-0.0031622776601683794|0.005226328339831627] "m/s^2" ECU
  SG_ sig_16_2 : 16|2@1- (1.0,0.0) [-2.0|1.0] "" ECU
  SG_ sig_43_11 : 43|11@1+ (0.0010000000000000002,-0.31622776601683794) [-0.31622776601683794|1.7297722339831627] "s" ECU
  SG_ sig_42_2 : 42|2@0- (1.0,0.0) [-2.0|1.0] "" ECU
  SG_ sig_54_2 : 54|2@1- (1.0,0.0) [-2.0|1.0] "" ECU

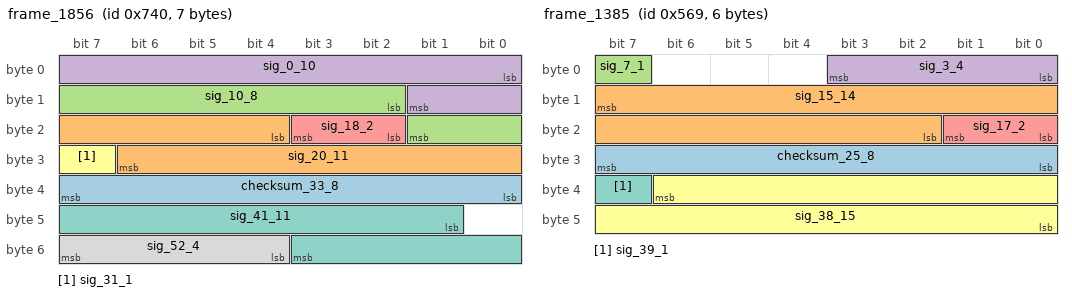
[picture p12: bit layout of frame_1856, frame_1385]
BO_ 1856 frame_1856: 7 Vector__XXX
  SG_ checksum_33_8 : 32|8@1+ (1.0,0.0) [0.0|255.0] "" ECU
  SG_ sig_20_11 : 20|11@1+ (1.0000000000000006E-5,0.0031622776601683794) [0.0031622776601683794|0.023622277660168393] "m/s^2" ECU
  SG_ sig_10_8 : 10|8@1+ (1.0,0.0) [0.0|254.0] "" ECU
  SG_ sig_0_10 : 0|10@1+ (0.0010000000000000002,-0.31622776601683794) [-0.31622776601683794|0.7057722339831622] "km/h" ECU
  SG_ sig_18_2 : 18|2@1+ (1.0,0.0) [0.0|3.0] "" ECU
  SG_ sig_31_1 : 31|1@1+ (1.0,0.0) [0.0|1.0] "" ECU
  SG_ sig_41_11 : 41|11@1- (1.0,0.0) [-1024.0|1022.0] "" ECU
  SG_ sig_52_4 : 52|4@1+ (0.1,-0.31622776601683794) [-0.31622776601683794|1.0837722339831621] "A" ECU

BO_ 74 frame_74: 4 Vector__XXX
  SG_ checksum_25_8 : 24|8@1+ (1.0,0.0) [0.0|255.0] "" ECU
  SG_ sig_7_11 : 7|11@0+ (1.0,0.0) [0.0|2046.0] "" ECU
  SG_ sig_12_13 : 12|13@0+ (1.0,0.0) [0.0|8190.0] "" ECU

BO_ 1779 frame_1779: 8 Vector__XXX
  SG_ checksum_9_8 : 15|8@0+ (1.0,0.0) [0.0|255.0] "" ECU
  SG_ sig_7_6 : 7|6@0- (1.0000000000000006E-6,-3.1622776601683795E-5) [-6.362277660168381E-5|-1.6227766016837776E-6] "m/s^2" ECU
  SG_ sig_1_2 : 1|2@0+ (1.0,0.0) [0.0|3.0] "" ECU
  SG_ sig_21_24 : 21|24@0+ (1.0000000000000005E-4,-316.22776601683796) [-316.22776601683796|1361.493633983163] "km/h" ECU
  SG_ sig_43_10 : 43|10@0+ (1.0,0.0) [0.0|1022.0] "" ECU
  SG_ sig_63_8 : 63|8@0- (100.0,-3162.2776601683795) [-15962.27766016838|9437.72233983162] "km/h" ECU

BO_ 1385 frame_1385: 6 ECU
  SG_ checksum_25_8 : 31|8@0+ (1.0,0.0) [0.0|255.0] "" Vector__XXX
  SG_ sig_15_14 : 15|14@0+ (1.0000000000000008E-8,0.0) [0.0|1.6382000000000015E-4] "kWh" Vector__XXX
  SG_ sig_7_1 : 7|1@0+ (1.0,0.0) [0.0|1.0] "" Vector__XXX
  SG_ sig_3_4 : 3|4@0- (0.010000000000000002,0.0) [-0.08000000000000002|0.06000000000000001] "W" Vector__XXX
  SG_ sig_17_2 : 17|2@0+ (1.0,0.0) [0.0|3.0] "" Vector__XXX
  SG_ sig_38_15 : 38|15@0- (1.0,0.0) [-16384.0|16382.0] "" Vector__XXX
  SG_ sig_39_1 : 39|1@0+ (1.0,0.0) [0.0|1.0] "" Vector__XXX

BO_ 425 frame_425: 6 Vector__XXX
  SG_ checksum_33_8 : 39|8@0+ (1.0,0.0) [0.0|255.0] "" ECU
  SG_ sig_4_18 : 4|18@1+ (1.0,0.0) [0.0|262142.0] "" ECU
  SG_ sig_3_1 : 3|1@1+ (1.0,0.0) [0.0|1.0] "" ECU
  SG_ sig_24_8 : 24|8@1- (1000.0,-31622.776601683792) [-159622.77660168378|94377.22339831622] "s" ECU
  SG_ sig_23_2 : 23|2@0+ (1.0,0.0) [0.0|3.0] "" ECU
  SG_ sig_40_8 : 40|8@1- (1.0000000000000006E-5,-3.1622776601683794E-4) [-0.0015962277660168387|9.437722339831628E-4] "A" ECU

BO_ 1697 frame_1697: 6 Vector__XXX
  SG_ checksum_9_8 : 8|8@1+ (1.0,0.0) [0.0|255.0] "" ECU
  SG_ sig_0_4 : 0|4@1- (0.1,-0.31622776601683794) [-1.116227766016838|0.28377223398316215] "kWh" ECU
  SG_ sig_24_8 : 24|8@0+ (1.0,0.0) [0.0|254.0] "" ECU
  SG_ sig_16_8 : 16|8@1+ (100.0,-3162.2776601683795) [-3162.2776601683795|22237.72233983162] "V" ECU
  SG_ sig_30_5 : 30|5@0+ (1.0000000000000005E-4,0.0031622776601683794) [0.0031622776601683794|0.006162277660168381] "V" ECU
  SG_ sig_25_1 : 25|1@1+ (1.0,0.0) [0.0|1.0] "" ECU
  SG_ sig_40_1 : 40|1@1+ (1.0,0.0) [0.0|1.0] "" ECU

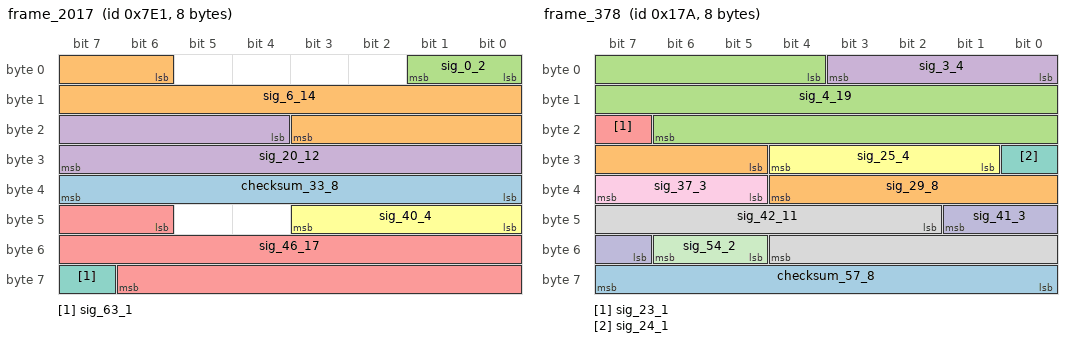
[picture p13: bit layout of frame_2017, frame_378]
BO_ 2017 frame_2017: 8 ECU
  SG_ checksum_33_8 : 32|8@1+ (1.0,0.0) [0.0|255.0] "" Vector__XXX
  SG_ sig_6_14 : 6|14@1- (1.0,0.0) [-8192.0|8190.0] "" Vector__XXX
  SG_ sig_0_2 : 0|2@1+ (1.0,0.0) [0.0|3.0] "" Vector__XXX
  SG_ sig_20_12 : 20|12@1+ (1.0,0.0) [0.0|4094.0] "" Vector__XXX
  SG_ sig_46_17 : 46|17@1- (1.0000000000000006E-5,0.31622776601683794) [-0.33913223398316245|0.9715677660168383] "s" Vector__XXX
  SG_ sig_40_4 : 40|4@1- (10000.0,-31622.776601683792) [-111622.77660168378|28377.223398316208] "m/s^2" Vector__XXX
  SG_ sig_63_1 : 63|1@1+ (1.0,0.0) [0.0|1.0] "" Vector__XXX

BO_ 378 frame_378: 8 Vector__XXX
  SG_ checksum_57_8 : 63|8@0+ (1.0,0.0) [0.0|255.0] "" ECU
  SG_ sig_29_8 : 29|8@1- (1.0,0.0) [-128.0|126.0] "" ECU
  SG_ sig_4_19 : 4|19@1- (1.0000000000000006E-5,3.1622776601683795) [0.540837660168378|5.7836976601683805] "V" ECU
  SG_ sig_3_4 : 3|4@0+ (10000.0,-31622.776601683792) [-31622.776601683792|108377.22339831622] "A" ECU
  SG_ sig_23_1 : 23|1@0+ (1.0,0.0) [0.0|1.0] "" ECU
  SG_ sig_25_4 : 25|4@1+ (1.0,0.0) [0.0|14.0] "" ECU
  SG_ sig_24_1 : 24|1@1+ (1.0,0.0) [0.0|1.0] "" ECU
  SG_ sig_42_11 : 42|11@1+ (1.0000000000000007E-7,0.0) [0.0|2.0460000000000015E-4] "km/h" ECU
  SG_ sig_37_3 : 37|3@1- (1.0,0.0) [-4.0|2.0] "" ECU
  SG_ sig_41_3 : 41|3@0- (1.0,0.0) [-4.0|2.0] "" ECU
  SG_ sig_54_2 : 54|2@0+ (1.0,0.0) [0.0|3.0] "" ECU

BO_ 814 frame_814: 1 Vector__XXX
  SG_ checksum_1_8 : 0|8@1+ (1.0,0.0) [0.0|255.0] "" ECU

BO_ 929 frame_929: 7 Vector__XXX
  SG_ checksum_41_8 : 40|8@1+ (1.0,0.0) [0.0|255.0] "" ECU
  SG_ sig_2_36 : 2|36@1+ (1.0000000000000014E-14,-3.1622776601683794E-4) [-3.1622776601683794E-4|3.709670013231631E-4] "V" ECU
  SG_ sig_1_2 : 1|2@0+ (1.0,0.0) [0.0|3.0] "" ECU
  SG_ sig_49_4 : 49|4@1- (1.0,0.0) [-8.0|6.0] "" ECU
  SG_ sig_55_3 : 55|3@0- (1.0,0.0) [-4.0|2.0] "" ECU
  SG_ sig_48_1 : 48|1@1+ (1.0,0.0) [0.0|1.0] "" ECU

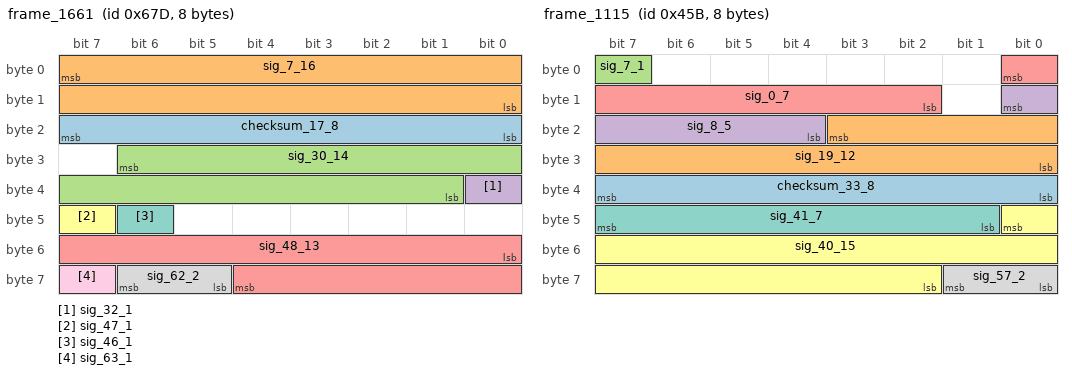
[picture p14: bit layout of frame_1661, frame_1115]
BO_ 1661 frame_1661: 8 Vector__XXX
  SG_ checksum_17_8 : 16|8@1+ (1.0,0.0) [0.0|255.0] "" ECU
  SG_ sig_7_16 : 7|16@0+ (1.0,0.0) [0.0|65534.0] "" ECU
  SG_ sig_30_14 : 30|14@0+ (0.0010000000000000002,3.1622776601683795) [3.1622776601683795|19.544277660168383] "km/h" ECU
  SG_ sig_32_1 : 32|1@1+ (1.0,0.0) [0.0|1.0] "" ECU
  SG_ sig_48_13 : 48|13@1+ (10.0,0.0) [0.0|81900.0] "kWh" ECU
  SG_ sig_47_1 : 47|1@0+ (1.0,0.0) [0.0|1.0] "" ECU
  SG_ sig_46_1 : 46|1@0+ (1.0,0.0) [0.0|1.0] "" ECU
  SG_ sig_62_2 : 62|2@0+ (1.0,0.0) [0.0|3.0] "" ECU
  SG_ sig_63_1 : 63|1@0+ (1.0,0.0) [0.0|1.0] "" ECU

BO_ 1115 frame_1115: 8 Vector__XXX
  SG_ checksum_33_8 : 39|8@0+ (1.0,0.0) [0.0|255.0] "" ECU
  SG_ sig_19_12 : 19|12@0+ (1.0000000000000009E-9,0.0) [0.0|4.0940000000000035E-6] "A" ECU
  SG_ sig_7_1 : 7|1@0+ (1.0,0.0) [0.0|1.0] "" ECU
  SG_ sig_8_5 : 8|5@0+ (0.010000000000000002,0.31622776601683794) [0.31622776601683794|0.616227766016838] "km/h" ECU
  SG_ sig_0_7 : 0|7@0- (1.0000000000000007E-7,-3.162277660168379E-6) [-9.562277660168384E-6|3.037722339831626E-6] "W" ECU
  SG_ sig_40_15 : 40|15@0+ (1.0,0.0) [0.0|32766.0] "" ECU
  SG_ sig_41_7 : 41|7@1+ (1.0,0.0) [0.0|126.0] "" ECU
  SG_ sig_57_2 : 57|2@0+ (1.0,0.0) [0.0|3.0] "" ECU

BO_ 1540 frame_1540: 6 Vector__XXX
  SG_ checksum_25_8 : 24|8@1+ (1.0,0.0) [0.0|255.0] "" ECU
  SG_ sig_6_13 : 6|13@1- (0.0010000000000000002,0.0) [-4.096000000000001|4.094000000000001] "V" ECU
  SG_ sig_0_5 : 0|5@1- (0.1,3.1622776601683795) [1.5622776601683794|4.562277660168379] "m/s^2" ECU
  SG_ sig_23_4 : 23|4@0- (1.0,0.0) [-8.0|6.0] "" ECU
  SG_ sig_38_13 : 38|13@0- (1.0,0.0) [-4096.0|4094.0] "" ECU
  SG_ sig_39_1 : 39|1@0+ (1.0,0.0) [0.0|1.0] "" ECU

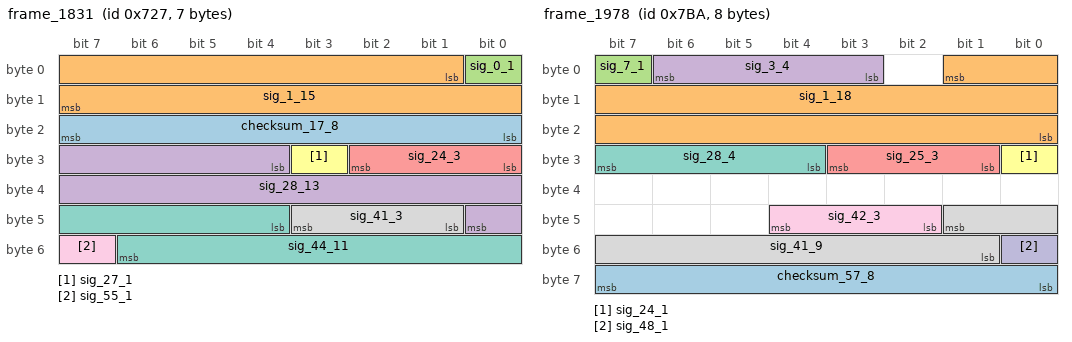
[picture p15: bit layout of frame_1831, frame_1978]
BO_ 1831 frame_1831: 7 Vector__XXX
  SG_ checksum_17_8 : 16|8@1+ (1.0,0.0) [0.0|255.0] "" ECU
  SG_ sig_1_15 : 1|15@1- (1.0000000000000006E-6,0.03162277660168379) [0.015238776601683782|0.0480047766016838] "kWh" ECU
  SG_ sig_0_1 : 0|1@1+ (1.0,0.0) [0.0|1.0] "" ECU
  SG_ sig_28_13 : 28|13@1+ (1.0,0.0) [0.0|8190.0] "" ECU
  SG_ sig_24_3 : 24|3@1- (1.0,0.0) [-4.0|2.0] "" ECU
  SG_ sig_27_1 : 27|1@1+ (1.0,0.0) [0.0|1.0] "" ECU
  SG_ sig_44_11 : 44|11@1+ (0.1,-31.622776601683793) [-31.622776601683793|172.97722339831623] "V" ECU
  SG_ sig_41_3 : 41|3@1- (1.0,0.0) [-4.0|2.0] "" ECU
  SG_ sig_55_1 : 55|1@1+ (1.0,0.0) [0.0|1.0] "" ECU

BO_ 1978 frame_1978: 8 Vector__XXX
  SG_ checksum_57_8 : 63|8@0+ (1.0,0.0) [0.0|255.0] "" ECU
  SG_ sig_1_18 : 1|18@0- (1.0,0.0) [-131072.0|131070.0] "" ECU
  SG_ sig_7_1 : 7|1@1+ (1.0,0.0) [0.0|1.0] "" ECU
  SG_ sig_3_4 : 3|4@1- (1.0,0.0) [-8.0|6.0] "" ECU
  SG_ sig_25_3 : 25|3@1+ (1.0,0.0) [0.0|6.0] "" ECU
  SG_ sig_24_1 : 24|1@1+ (1.0,0.0) [0.0|1.0] "" ECU
  SG_ sig_28_4 : 28|4@1+ (1000.0,-3162.2776601683795) [-3162.2776601683795|10837.72233983162] "m/s^2" ECU
  SG_ sig_41_9 : 41|9@0+ (1.0000000000000008E-8,-3.162277660168379E-6) [-3.162277660168379E-6|1.9377223398316253E-6] "V" ECU
  SG_ sig_42_3 : 42|3@1- (1.0,0.0) [-4.0|2.0] "" ECU
  SG_ sig_48_1 : 48|1@0+ (1.0,0.0) [0.0|1.0] "" ECU

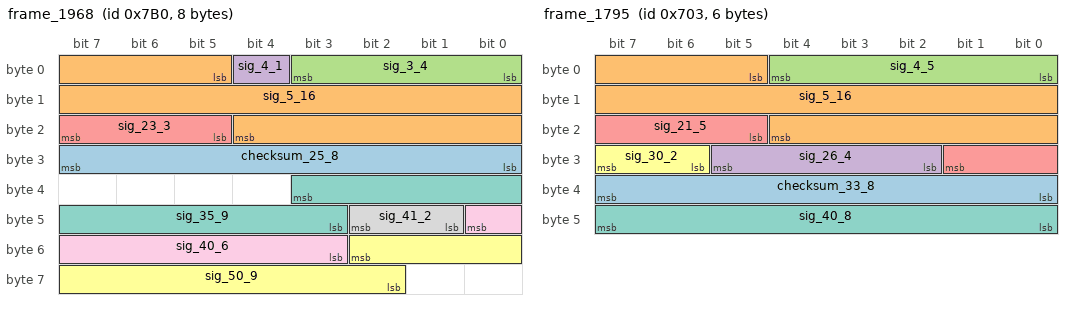
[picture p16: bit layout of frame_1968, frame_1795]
BO_ 1968 frame_1968: 8 Vector__XXX
  SG_ checksum_25_8 : 31|8@0+ (1.0,0.0) [0.0|255.0] "" ECU
  SG_ sig_5_16 : 5|16@1+ (0.1,3162.2776601683795) [3162.2776601683795|9715.67766016838] "m/s^2" ECU
  SG_ sig_3_4 : 3|4@0- (10000.0,31622.776601683792) [-48377.22339831621|91622.77660168378] "kWh" ECU
  SG_ sig_4_1 : 4|1@1+ (1.0,0.0) [0.0|1.0] "" ECU
  SG_ sig_23_3 : 23|3@0- (1.0,0.0) [-4.0|2.0] "" ECU
  SG_ sig_50_9 : 50|9@0- (1.0,0.0) [-256.0|254.0] "V" ECU
  SG_ sig_35_9 : 35|9@0+ (1.0,0.0) [0.0|510.0] "km/h" ECU
  SG_ sig_41_2 : 41|2@1- (1.0,0.0) [-2.0|1.0] "" ECU
  SG_ sig_40_6 : 40|6@0- (0.0010000000000000002,0.0) [-0.03200000000000001|0.030000000000000006] "kWh" ECU

BO_ 1795 frame_1795: 6 Vector__XXX
  SG_ checksum_33_8 : 32|8@1+ (1.0,0.0) [0.0|255.0] "" ECU
  SG_ sig_5_16 : 5|16@1- (1.0000000000000009E-9,0.0) [-3.276800000000003E-5|3.276600000000003E-5] "s" ECU
  SG_ sig_4_5 : 4|5@0- (1.0,0.0) [-16.0|14.0] "" ECU
  SG_ sig_26_4 : 26|4@1+ (1.0,0.0) [0.0|14.0] "" ECU
  SG_ sig_21_5 : 21|5@1+ (10.0,-316.22776601683796) [-316.22776601683796|-16.22776601683796] "s" ECU
  SG_ sig_30_2 : 30|2@1+ (1.0,0.0) [0.0|3.0] "" ECU
  SG_ sig_40_8 : 40|8@1+ (1.0,0.0) [0.0|254.0] "" ECU

BO_ 545 frame_545: 2 Vector__XXX
  SG_ checksum_1_8 : 0|8@1+ (1.0,0.0) [0.0|255.0] "" ECU
  SG_ sig_14_5 : 14|5@0+ (1.0000000000000006E-5,3.1622776601683794E-4) [3.1622776601683794E-4|6.162277660168381E-4] "A" ECU
  SG_ sig_15_1 : 15|1@0+ (1.0,0.0) [0.0|1.0] "" ECU
  SG_ sig_8_2 : 8|2@1- (1.0,0.0) [-2.0|1.0] "" ECU

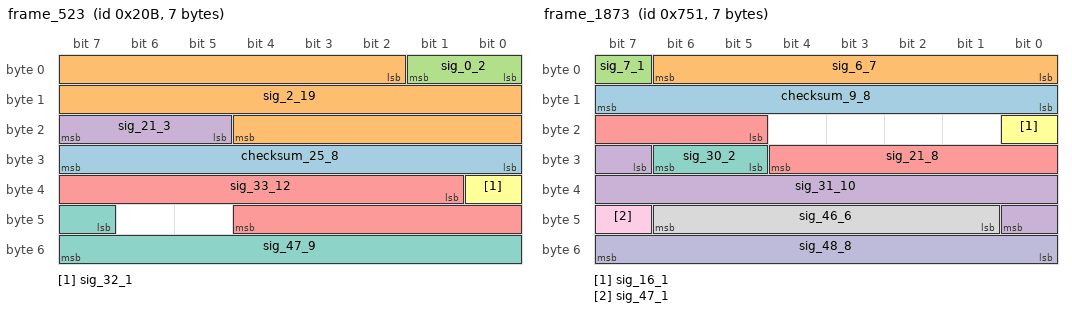
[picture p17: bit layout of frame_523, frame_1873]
BO_ 523 frame_523: 7 ECU
  SG_ checksum_25_8 : 31|8@0+ (1.0,0.0) [0.0|255.0] "" Vector__XXX
  SG_ sig_2_19 : 2|19@1+ (1.000000000000001E-11,3.162277660168379E-6) [3.162277660168379E-6|8.405137660168385E-6] "kWh" Vector__XXX
  SG_ sig_0_2 : 0|2@1- (1.0,0.0) [-2.0|1.0] "" Vector__XXX
  SG_ sig_21_3 : 21|3@1+ (1.0,0.0) [0.0|6.0] "" Vector__XXX
  SG_ sig_33_12 : 33|12@1- (1.0000000000000009E-9,3.162277660168379E-6) [1.1142776601683774E-6|5.208277660168381E-6] "s" Vector__XXX
  SG_ sig_32_1 : 32|1@1+ (1.0,0.0) [0.0|1.0] "" Vector__XXX
  SG_ sig_47_9 : 47|9@1+ (0.1,0.0) [0.0|51.0] "m/s^2" Vector__XXX

BO_ 1873 frame_1873: 7 Vector__XXX
  SG_ checksum_9_8 : 15|8@0+ (1.0,0.0) [0.0|255.0] "" ECU
  SG_ sig_6_7 : 6|7@0+ (1.0,0.0) [0.0|126.0] "" ECU
  SG_ sig_7_1 : 7|1@0+ (1.0,0.0) [0.0|1.0] "" ECU
  SG_ sig_31_10 : 31|10@1- (1.0,0.0) [-512.0|510.0] "" ECU
  SG_ sig_21_8 : 21|8@1- (1.0,0.0) [-128.0|126.0] "kWh" ECU
  SG_ sig_16_1 : 16|1@0+ (1.0,0.0) [0.0|1.0] "" ECU
  SG_ sig_30_2 : 30|2@0- (1.0,0.0) [-2.0|1.0] "" ECU
  SG_ sig_46_6 : 46|6@0+ (0.1,-3.1622776601683795) [-3.1622776601683795|3.0377223398316207] "V" ECU
  SG_ sig_47_1 : 47|1@0+ (1.0,0.0) [0.0|1.0] "" ECU
  SG_ sig_48_8 : 48|8@1- (1.0,0.0) [-128.0|126.0] "" ECU

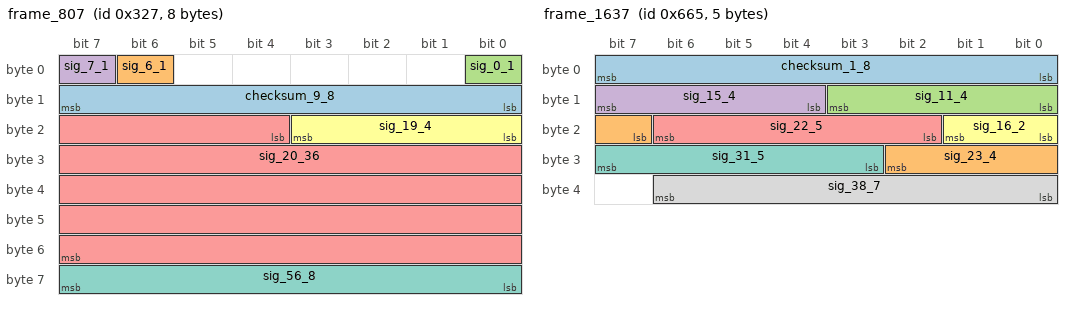
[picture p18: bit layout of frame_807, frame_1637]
BO_ 807 frame_807: 8 ECU
  SG_ checksum_9_8 : 15|8@0+ (1.0,0.0) [0.0|255.0] "" Vector__XXX
  SG_ sig_6_1 : 6|1@0+ (1.0,0.0) [0.0|1.0] "" Vector__XXX
  SG_ sig_0_1 : 0|1@1+ (1.0,0.0) [0.0|1.0] "" Vector__XXX
  SG_ sig_7_1 : 7|1@0+ (1.0,0.0) [0.0|1.0] "" Vector__XXX
  SG_ sig_20_36 : 20|36@1+ (1.000000000000001E-11,0.0) [0.0|0.6871947673400007] "km/h" Vector__XXX
  SG_ sig_19_4 : 19|4@0- (10.0,0.0) [-80.0|60.0] "A" Vector__XXX
  SG_ sig_56_8 : 56|8@1- (0.010000000000000002,-0.31622776601683794) [-1.5962277660168382|0.9437722339831622] "s" Vector__XXX

BO_ 1637 frame_1637: 5 ECU
  SG_ checksum_1_8 : 0|8@1+ (1.0,0.0) [0.0|255.0] "" Vector__XXX
  SG_ sig_23_4 : 23|4@1- (1.0,0.0) [-8.0|6.0] "" Vector__XXX
  SG_ sig_11_4 : 11|4@0- (1.0,0.0) [-8.0|6.0] "" Vector__XXX
  SG_ sig_15_4 : 15|4@0+ (1.0000000000000006E-5,0.0) [0.0|1.400000000000001E-4] "W" Vector__XXX
  SG_ sig_22_5 : 22|5@0- (1.0,0.0) [-16.0|14.0] "" Vector__XXX
  SG_ sig_16_2 : 16|2@1- (1.0,0.0) [-2.0|1.0] "" Vector__XXX
  SG_ sig_31_5 : 31|5@0- (1.0,0.0) [-16.0|14.0] "" Vector__XXX
  SG_ sig_38_7 : 38|7@0+ (1.0,0.0) [0.0|126.0] "" Vector__XXX

BO_ 1612 frame_1612: 6 Vector__XXX
  SG_ checksum_25_8 : 24|8@1+ (1.0,0.0) [0.0|255.0] "" ECU
  SG_ sig_4_15 : 4|15@0+ (1.0000000000000011E-10,3.162277660168379E-6) [3.162277660168379E-6|6.438877660168383E-6] "V" ECU
  SG_ sig_5_3 : 5|3@1+ (1.0,0.0) [0.0|6.0] "" ECU
  SG_ sig_21_6 : 21|6@0- (1.0,0.0) [-32.0|30.0] "" ECU
  SG_ sig_40_8 : 40|8@1+ (1.0000000000000006E-5,-3.1622776601683794E-4) [-3.1622776601683794E-4|0.0022237722339831633] "W" ECU
  SG_ sig_39_8 : 39|8@0- (1.0000000000000006E-6,3.1622776601683795E-5) [-9.637722339831629E-5|1.5762277660168387E-4] "W" ECU

BO_ 214 frame_214: 7 Vector__XXX
  SG_ checksum_17_8 : 16|8@1+ (1.0,0.0) [0.0|255.0] "" ECU
  SG_ sig_0_16 : 0|16@1- (1.0000000000000006E-6,0.0) [-0.03276800000000002|0.03276600000000002] "A" ECU
  SG_ sig_36_19 : 36|19@1- (1.0,0.0) [-262144.0|262142.0] "" ECU
  SG_ sig_24_1 : 24|1@1+ (1.0,0.0) [0.0|1.0] "" ECU
  SG_ sig_55_1 : 55|1@1+ (1.0,0.0) [0.0|1.0] "" ECU

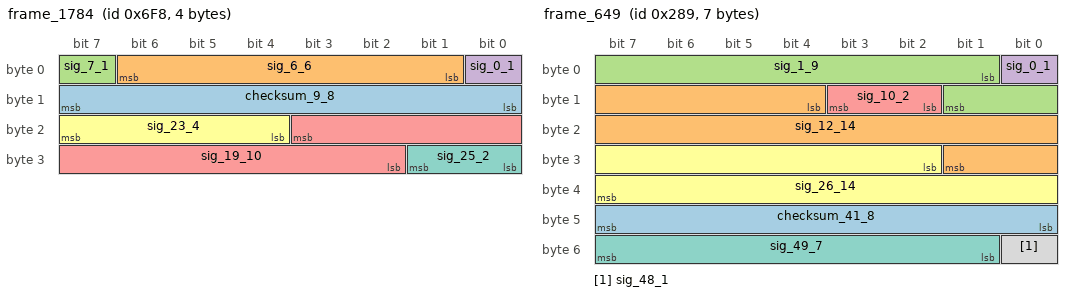
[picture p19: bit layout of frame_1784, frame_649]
BO_ 1784 frame_1784: 4 ECU
  SG_ checksum_9_8 : 15|8@0+ (1.0,0.0) [0.0|255.0] "" Vector__XXX
  SG_ sig_6_6 : 6|6@0+ (1.0,0.0) [0.0|62.0] "" Vector__XXX
  SG_ sig_7_1 : 7|1@0+ (1.0,0.0) [0.0|1.0] "" Vector__XXX
  SG_ sig_0_1 : 0|1@0+ (1.0,0.0) [0.0|1.0] "" Vector__XXX
  SG_ sig_19_10 : 19|10@0+ (1.0,0.0) [0.0|1022.0] "" Vector__XXX
  SG_ sig_23_4 : 23|4@0- (0.1,0.31622776601683794) [-0.4837722339831621|0.9162277660168381] "m/s^2" Vector__XXX
  SG_ sig_25_2 : 25|2@0+ (1.0,0.0) [0.0|3.0] "" Vector__XXX

BO_ 649 frame_649: 7 ECU
  SG_ checksum_41_8 : 40|8@1+ (1.0,0.0) [0.0|255.0] "" Vector__XXX
  SG_ sig_12_14 : 12|14@1- (1.0000000000000006E-5,0.0) [-0.08192000000000005|0.08190000000000004] "A" Vector__XXX
  SG_ sig_1_9 : 1|9@1+ (1.0,0.0) [0.0|510.0] "" Vector__XXX
  SG_ sig_0_1 : 0|1@1+ (1.0,0.0) [0.0|1.0] "" Vector__XXX
  SG_ sig_10_2 : 10|2@1- (1.0,0.0) [-2.0|1.0] "" Vector__XXX
  SG_ sig_26_14 : 26|14@1+ (1.0000000000000006E-6,0.0) [0.0|0.01638200000000001] "km/h" Vector__XXX
  SG_ sig_49_7 : 49|7@1- (1.0000000000000005E-4,0.0) [-0.006400000000000003|0.006200000000000002] "A" Vector__XXX
  SG_ sig_48_1 : 48|1@1+ (1.0,0.0) [0.0|1.0] "" Vector__XXX

CM_ BO_ 1519 "Randomly defined CAN frame";
CM_ SG_ 1519 checksum_1_8 "8 Bit checksum for protection of frame contents";
CM_ BO_ 661 "Randomly defined CAN frame";
CM_ SG_ 661 checksum_9_8 "8 Bit checksum for protection of frame contents";
CM_ BO_ 1084 "Randomly defined CAN frame";
CM_ SG_ 1084 checksum_1_8 "8 Bit checksum for protection of frame contents";
CM_ BO_ 888 "Randomly defined CAN frame";
CM_ SG_ 888 checksum_17_8 "8 Bit checksum for protection of frame contents";
CM_ BO_ 1170 "Randomly defined CAN frame";
CM_ SG_ 1170 checksum_1_8 "8 Bit checksum for protection of frame contents";
CM_ BO_ 1320 "Randomly defined CAN frame";
CM_ SG_ 1320 checksum_49_8 "8 Bit checksum for protection of frame contents";
CM_ BO_ 1696 "Randomly defined CAN frame";
CM_ SG_ 1696 checksum_17_8 "8 Bit checksum for protection of frame contents";
CM_ BO_ 1162 "Randomly defined CAN frame";
CM_ SG_ 1162 checksum_25_8 "8 Bit checksum for protection of frame contents";
CM_ BO_ 1398 "Randomly defined CAN frame";
CM_ SG_ 1398 checksum_49_8 "8 Bit checksum for protection of frame contents";
CM_ BO_ 187 "Randomly defined CAN frame";
CM_ SG_ 187 checksum_1_8 "8 Bit checksum for protection of frame contents";
CM_ BO_ 428 "Randomly defined CAN frame";
CM_ SG_ 428 checksum_9_8 "8 Bit checksum for protection of frame contents";
CM_ BO_ 1425 "Randomly defined CAN frame";
CM_ SG_ 1425 checksum_25_8 "8 Bit checksum for protection of frame contents";
CM_ BO_ 1217 "Randomly defined CAN frame";
CM_ SG_ 1217 checksum_17_8 "8 Bit checksum for protection of frame contents";
CM_ BO_ 456 "Randomly defined CAN frame";
CM_ SG_ 456 checksum_9_8 "8 Bit checksum for protection of frame contents";
CM_ BO_ 1627 "Randomly defined CAN frame";
CM_ SG_ 1627 checksum_57_8 "8 Bit checksum for protection of frame contents";
CM_ BO_ 804 "Randomly defined CAN frame";
CM_ SG_ 804 checksum_9_8 "8 Bit checksum for protection of frame contents";
CM_ BO_ 1154 "Randomly defined CAN frame";
CM_ SG_ 1154 checksum_25_8 "8 Bit checksum for protection of frame contents";
CM_ BO_ 1404 "Randomly defined CAN frame";
CM_ SG_ 1404 checksum_41_8 "8 Bit checksum for protection of frame contents";
CM_ BO_ 259 "Randomly defined CAN frame";
CM_ SG_ 259 checksum_1_8 "8 Bit checksum for protection of frame contents";
CM_ BO_ 1374 "Randomly defined CAN frame";
CM_ SG_ 1374 checksum_17_8 "8 Bit checksum for protection of frame contents";
CM_ BO_ 820 "Randomly defined CAN frame";
CM_ SG_ 820 checksum_25_8 "8 Bit checksum for protection of frame contents";
CM_ BO_ 1433 "Randomly defined CAN frame";
CM_ SG_ 1433 checksum_41_8 "8 Bit checksum for protection of frame contents";
CM_ BO_ 1820 "Randomly defined CAN frame";
CM_ SG_ 1820 checksum_25_8 "8 Bit checksum for protection of frame contents";
CM_ BO_ 1909 "Randomly defined CAN frame";
CM_ SG_ 1909 checksum_41_8 "8 Bit checksum for protection of frame contents";
CM_ BO_ 1713 "Randomly defined CAN frame";
CM_ SG_ 1713 checksum_1_8 "8 Bit checksum for protection of frame contents";
CM_ BO_ 1318 "Randomly defined CAN frame";
CM_ SG_ 1318 checksum_9_8 "8 Bit checksum for protection of frame contents";
CM_ BO_ 1068 "Randomly defined CAN frame";
CM_ SG_ 1068 checksum_17_8 "8 Bit checksum for protection of frame contents";
CM_ BO_ 1670 "Randomly defined CAN frame";
CM_ SG_ 1670 checksum_9_8 "8 Bit checksum for protection of frame contents";
CM_ BO_ 1300 "Randomly defined CAN frame";
CM_ SG_ 1300 checksum_9_8 "8 Bit checksum for protection of frame contents";
CM_ BO_ 1446 "Randomly defined CAN frame";
CM_ SG_ 1446 checksum_57_8 "8 Bit checksum for protection of frame contents";
CM_ BO_ 144 "Randomly defined CAN frame";
CM_ SG_ 144 checksum_25_8 "8 Bit checksum for protection of frame contents";
CM_ BO_ 1029 "Randomly defined CAN frame";
CM_ SG_ 1029 checksum_9_8 "8 Bit checksum for protection of frame contents";
CM_ BO_ 23 "Randomly defined CAN frame";
CM_ SG_ 23 checksum_33_8 "8 Bit checksum for protection of frame contents";
CM_ BO_ 1485 "Randomly defined CAN frame";
CM_ SG_ 1485 checksum_49_8 "8 Bit checksum for protection of frame contents";
CM_ BO_ 1262 "Randomly defined CAN frame";
CM_ SG_ 1262 checksum_33_8 "8 Bit checksum for protection of frame contents";
CM_ BO_ 1512 "Randomly defined CAN frame";
CM_ SG_ 1512 checksum_49_8 "8 Bit checksum for protection of frame contents";
CM_ BO_ 912 "Randomly defined CAN frame";
CM_ SG_ 912 checksum_25_8 "8 Bit checksum for protection of frame contents";
CM_ BO_ 1979 "Randomly defined CAN frame";
CM_ SG_ 1979 checksum_9_8 "8 Bit checksum for protection of frame contents";
CM_ BO_ 1856 "Randomly defined CAN frame";
CM_ SG_ 1856 checksum_33_8 "8 Bit checksum for protection of frame contents";
CM_ BO_ 74 "Randomly defined CAN frame";
CM_ SG_ 74 checksum_25_8 "8 Bit checksum for protection of frame contents";
CM_ BO_ 1779 "Randomly defined CAN frame";
CM_ SG_ 1779 checksum_9_8 "8 Bit checksum for protection of frame contents";
CM_ BO_ 1385 "Randomly defined CAN frame";
CM_ SG_ 1385 checksum_25_8 "8 Bit checksum for protection of frame contents";
CM_ BO_ 425 "Randomly defined CAN frame";
CM_ SG_ 425 checksum_33_8 "8 Bit checksum for protection of frame contents";
CM_ BO_ 1697 "Randomly defined CAN frame";
CM_ SG_ 1697 checksum_9_8 "8 Bit checksum for protection of frame contents";
CM_ BO_ 2017 "Randomly defined CAN frame";
CM_ SG_ 2017 checksum_33_8 "8 Bit checksum for protection of frame contents";
CM_ BO_ 378 "Randomly defined CAN frame";
CM_ SG_ 378 checksum_57_8 "8 Bit checksum for protection of frame contents";
CM_ BO_ 814 "Randomly defined CAN frame";
CM_ SG_ 814 checksum_1_8 "8 Bit checksum for protection of frame contents";
CM_ BO_ 929 "Randomly defined CAN frame";
CM_ SG_ 929 checksum_41_8 "8 Bit checksum for protection of frame contents";
CM_ BO_ 1661 "Randomly defined CAN frame";
CM_ SG_ 1661 checksum_17_8 "8 Bit checksum for protection of frame contents";
CM_ BO_ 1115 "Randomly defined CAN frame";
CM_ SG_ 1115 checksum_33_8 "8 Bit checksum for protection of frame contents";
CM_ BO_ 1540 "Randomly defined CAN frame";
CM_ SG_ 1540 checksum_25_8 "8 Bit checksum for protection of frame contents";
CM_ BO_ 1831 "Randomly defined CAN frame";
CM_ SG_ 1831 checksum_17_8 "8 Bit checksum for protection of frame contents";
CM_ BO_ 1978 "Randomly defined CAN frame";
CM_ SG_ 1978 checksum_57_8 "8 Bit checksum for protection of frame contents";
CM_ BO_ 1968 "Randomly defined CAN frame";
CM_ SG_ 1968 checksum_25_8 "8 Bit checksum for protection of frame contents";
CM_ BO_ 1795 "Randomly defined CAN frame";
CM_ SG_ 1795 checksum_33_8 "8 Bit checksum for protection of frame contents";
CM_ BO_ 545 "Randomly defined CAN frame";
CM_ SG_ 545 checksum_1_8 "8 Bit checksum for protection of frame contents";
CM_ BO_ 523 "Randomly defined CAN frame";
CM_ SG_ 523 checksum_25_8 "8 Bit checksum for protection of frame contents";
CM_ BO_ 1873 "Randomly defined CAN frame";
CM_ SG_ 1873 checksum_9_8 "8 Bit checksum for protection of frame contents";
CM_ BO_ 807 "Randomly defined CAN frame";
CM_ SG_ 807 checksum_9_8 "8 Bit checksum for protection of frame contents";
CM_ BO_ 1637 "Randomly defined CAN frame";
CM_ SG_ 1637 checksum_1_8 "8 Bit checksum for protection of frame contents";
CM_ BO_ 1612 "Randomly defined CAN frame";
CM_ SG_ 1612 checksum_25_8 "8 Bit checksum for protection of frame contents";
CM_ BO_ 214 "Randomly defined CAN frame";
CM_ SG_ 214 checksum_17_8 "8 Bit checksum for protection of frame contents";
CM_ BO_ 1784 "Randomly defined CAN frame";
CM_ SG_ 1784 checksum_9_8 "8 Bit checksum for protection of frame contents";
CM_ BO_ 649 "Randomly defined CAN frame";
CM_ SG_ 649 checksum_41_8 "8 Bit checksum for protection of frame contents";
BA_DEF_ "Author" STRING;
BA_DEF_ BO_ "frameSendMode" ENUM  "regular","event","mixed";
BA_DEF_ BO_ "sendPeriod" INT 5 10000;
BA_DEF_ BO_ "crcStartValue" INT 1 255;
BA_DEF_ BO_ "eventMinDistance" INT 5 10000;
BA_DEF_ SG_ "initialValue" FLOAT -1e38 1e38;
BA_DEF_DEF_ "Author" "http://sourceforge.net/projects/comframe/";
BA_DEF_DEF_ "frameSendMode" "regular";
BA_DEF_DEF_ "sendPeriod" 10;
BA_DEF_DEF_ "crcStartValue" 1;
BA_DEF_DEF_ "eventMinDistance" 10;
BA_DEF_DEF_ "initialValue" 0.0;
BA_ "sendPeriod" BO_ 1519 10000;
BA_ "crcStartValue" BO_ 1519 66;
BA_ "initialValue" SG_ 1519 sig_14_12 0.429627766016838;
BA_ "initialValue" SG_ 1519 sig_8_6 -31.0;
BA_ "initialValue" SG_ 1519 sig_27_5 4.26227766016838E-4;
BA_ "initialValue" SG_ 1519 sig_26_1 1.0;
BA_ "frameSendMode" BO_ 661 2;
BA_ "sendPeriod" BO_ 661 100;
BA_ "eventMinDistance" BO_ 661 50;
BA_ "crcStartValue" BO_ 661 80;
BA_ "initialValue" SG_ 661 sig_7_5 0.02162277660168379;
BA_ "initialValue" SG_ 661 sig_1_2 2.0;
BA_ "initialValue" SG_ 661 sig_0_1 1.0;
BA_ "initialValue" SG_ 661 sig_20_9 8.242277660168383E-4;
BA_ "initialValue" SG_ 661 sig_16_4 13.0;
BA_ "sendPeriod" BO_ 1084 100;
BA_ "crcStartValue" BO_ 1084 234;
BA_ "initialValue" SG_ 1084 sig_11_14 1.0867223398316245E-6;
BA_ "initialValue" SG_ 1084 sig_15_4 2.837722339831624E-5;
BA_ "sendPeriod" BO_ 888 500;
BA_ "crcStartValue" BO_ 888 215;
BA_ "initialValue" SG_ 888 sig_5_10 542.0;
BA_ "initialValue" SG_ 888 sig_1_4 -3.0;
BA_ "initialValue" SG_ 888 sig_0_1 1.0;
BA_ "initialValue" SG_ 888 sig_15_1 1.0;
BA_ "initialValue" SG_ 888 sig_34_14 -7.001277660168383E-6;
BA_ "initialValue" SG_ 888 sig_24_2 3.0;
BA_ "initialValue" SG_ 888 sig_32_2 3.0;
BA_ "sendPeriod" BO_ 1170 1000;
BA_ "crcStartValue" BO_ 1170 89;
BA_ "initialValue" SG_ 1170 sig_20_19 -19052.97660168379;
BA_ "initialValue" SG_ 1170 sig_15_8 0.16400000000000003;
BA_ "initialValue" SG_ 1170 sig_46_11 2.3362277660168385;
BA_ "initialValue" SG_ 1170 sig_47_1 1.0;
BA_ "initialValue" SG_ 1170 sig_49_2 -2.0;
BA_ "initialValue" SG_ 1170 sig_51_1 1.0;
BA_ "initialValue" SG_ 1170 sig_56_7 -2.377223398316234E-7;
BA_ "initialValue" SG_ 1170 sig_63_1 1.0;
BA_ "frameSendMode" BO_ 1320 2;
BA_ "sendPeriod" BO_ 1320 1000;
BA_ "eventMinDistance" BO_ 1320 1000;
BA_ "crcStartValue" BO_ 1320 167;
BA_ "initialValue" SG_ 1320 sig_38_2 -1.0;
BA_ "initialValue" SG_ 1320 sig_8_11 1284.0;
BA_ "initialValue" SG_ 1320 sig_1_6 -31.0;
BA_ "initialValue" SG_ 1320 sig_7_1 1.0;
BA_ "initialValue" SG_ 1320 sig_9_7 -0.486227766016838;
BA_ "initialValue" SG_ 1320 sig_29_7 890.0;
BA_ "initialValue" SG_ 1320 sig_34_11 563.0;
BA_ "initialValue" SG_ 1320 sig_56_8 4862.27766016838;
BA_ "sendPeriod" BO_ 1696 500;
BA_ "crcStartValue" BO_ 1696 231;
BA_ "initialValue" SG_ 1696 sig_0_16 5.5424776601683816E-5;
BA_ "initialValue" SG_ 1696 sig_32_9 2.0;
BA_ "initialValue" SG_ 1696 sig_27_10 79.8227766016838;
BA_ "initialValue" SG_ 1696 sig_28_4 -6.0;
BA_ "initialValue" SG_ 1696 sig_33_1 1.0;
BA_ "initialValue" SG_ 1696 sig_54_7 4.26227766016838E-4;
BA_ "frameSendMode" BO_ 1162 2;
BA_ "sendPeriod" BO_ 1162 10000;
BA_ "eventMinDistance" BO_ 1162 500;
BA_ "crcStartValue" BO_ 1162 160;
BA_ "initialValue" SG_ 1162 sig_4_13 0.13152776601683785;
BA_ "initialValue" SG_ 1162 sig_7_3 -3.0;
BA_ "initialValue" SG_ 1162 sig_21_3 1.0;
BA_ "initialValue" SG_ 1162 sig_23_2 -1.0;
BA_ "initialValue" SG_ 1162 sig_18_3 -2.0;
BA_ "initialValue" SG_ 1162 sig_38_7 423.77223398316204;
BA_ "frameSendMode" BO_ 1398 2;
BA_ "sendPeriod" BO_ 1398 1000;
BA_ "eventMinDistance" BO_ 1398 500;
BA_ "crcStartValue" BO_ 1398 107;
BA_ "initialValue" SG_ 1398 sig_5_3 -3.0;
BA_ "initialValue" SG_ 1398 sig_4_8 -9.562277660168383E-5;
BA_ "initialValue" SG_ 1398 sig_8_3 -3.0;
BA_ "initialValue" SG_ 1398 sig_23_25 642.6993560168382;
BA_ "initialValue" SG_ 1398 sig_40_1 1.0;
BA_ "initialValue" SG_ 1398 sig_63_7 9.0;
BA_ "initialValue" SG_ 1398 sig_56_1 1.0;
BA_ "sendPeriod" BO_ 187 500;
BA_ "crcStartValue" BO_ 187 188;
BA_ "initialValue" SG_ 187 sig_13_16 4979.0;
BA_ "initialValue" SG_ 187 sig_28_5 20.0;
BA_ "frameSendMode" BO_ 428 2;
BA_ "sendPeriod" BO_ 428 10000;
BA_ "eventMinDistance" BO_ 428 1000;
BA_ "crcStartValue" BO_ 428 219;
BA_ "initialValue" SG_ 428 sig_2_6 0.10377223398316215;
BA_ "initialValue" SG_ 428 sig_21_13 2047.0;
BA_ "initialValue" SG_ 428 sig_37_12 223.32776601683796;
BA_ "initialValue" SG_ 428 sig_24_1 1.0;
BA_ "initialValue" SG_ 428 sig_38_4 0.007000000000000002;
BA_ "sendPeriod" BO_ 1425 25;
BA_ "crcStartValue" BO_ 1425 10;
BA_ "initialValue" SG_ 1425 sig_7_16 38602.0;
BA_ "initialValue" SG_ 1425 sig_6_7 7.0;
BA_ "initialValue" SG_ 1425 sig_23_1 1.0;
BA_ "initialValue" SG_ 1425 sig_39_8 79.0;
BA_ "sendPeriod" BO_ 1217 5;
BA_ "crcStartValue" BO_ 1217 117;
BA_ "initialValue" SG_ 1217 sig_4_10 -501.0;
BA_ "frameSendMode" BO_ 456 2;
BA_ "sendPeriod" BO_ 456 1000;
BA_ "eventMinDistance" BO_ 456 500;
BA_ "crcStartValue" BO_ 456 21;
BA_ "initialValue" SG_ 456 sig_2_6 3.8622776601683797;
BA_ "initialValue" SG_ 456 sig_28_15 2643.6776601683796;
BA_ "initialValue" SG_ 456 sig_18_9 -1.6900000000000004;
BA_ "initialValue" SG_ 456 sig_16_2 2.0;
BA_ "initialValue" SG_ 456 sig_46_3 -1.0;
BA_ "initialValue" SG_ 456 sig_47_1 1.0;
BA_ "initialValue" SG_ 456 sig_43_1 1.0;
BA_ "initialValue" SG_ 456 sig_54_7 -1.0;
BA_ "frameSendMode" BO_ 1627 2;
BA_ "sendPeriod" BO_ 1627 1000;
BA_ "eventMinDistance" BO_ 1627 500;
BA_ "crcStartValue" BO_ 1627 132;
BA_ "initialValue" SG_ 1627 sig_32_1 1.0;
BA_ "initialValue" SG_ 1627 sig_21_9 11.822776601683792;
BA_ "initialValue" SG_ 1627 sig_7_9 -1.7300000000000004;
BA_ "initialValue" SG_ 1627 sig_13_6 56.0;
BA_ "initialValue" SG_ 1627 sig_20_7 32000.0;
BA_ "initialValue" SG_ 1627 sig_50_5 0.0030000000000000014;
BA_ "initialValue" SG_ 1627 sig_49_2 1.0;
BA_ "frameSendMode" BO_ 804 2;
BA_ "sendPeriod" BO_ 804 100;
BA_ "eventMinDistance" BO_ 804 50;
BA_ "crcStartValue" BO_ 804 226;
BA_ "initialValue" SG_ 804 sig_7_7 0.11362277660168381;
BA_ "initialValue" SG_ 804 sig_22_19 -1.839940000000002E-5;
BA_ "initialValue" SG_ 804 sig_34_19 -3.5073676601683796E-6;
BA_ "initialValue" SG_ 804 sig_35_1 1.0;
BA_ "sendPeriod" BO_ 1154 500;
BA_ "crcStartValue" BO_ 1154 243;
BA_ "initialValue" SG_ 1154 sig_7_15 -2587.7776601683795;
BA_ "initialValue" SG_ 1154 sig_19_4 -8.000000000000005E-5;
BA_ "initialValue" SG_ 1154 sig_23_2 1.0;
BA_ "initialValue" SG_ 1154 sig_38_6 -11.0;
BA_ "initialValue" SG_ 1154 sig_32_1 1.0;
BA_ "sendPeriod" BO_ 1404 20;
BA_ "crcStartValue" BO_ 1404 198;
BA_ "initialValue" SG_ 1404 sig_23_10 0.015400000000000007;
BA_ "initialValue" SG_ 1404 sig_0_11 1166.0;
BA_ "initialValue" SG_ 1404 sig_11_5 5162.27766016838;
BA_ "initialValue" SG_ 1404 sig_25_9 5.04227766016838;
BA_ "initialValue" SG_ 1404 sig_48_13 0.0076800000000000045;
BA_ "initialValue" SG_ 1404 sig_61_3 1.0;
BA_ "sendPeriod" BO_ 259 5;
BA_ "crcStartValue" BO_ 259 15;
BA_ "initialValue" SG_ 259 sig_13_17 0.013326776601683781;
BA_ "initialValue" SG_ 259 sig_11_4 716.2277660168379;
BA_ "sendPeriod" BO_ 1374 20;
BA_ "crcStartValue" BO_ 1374 174;
BA_ "initialValue" SG_ 1374 sig_7_12 3289.0;
BA_ "initialValue" SG_ 1374 sig_42_11 6.462277660168382E-4;
BA_ "initialValue" SG_ 1374 sig_29_9 0.2152277660168379;
BA_ "initialValue" SG_ 1374 sig_32_4 -8.0;
BA_ "initialValue" SG_ 1374 sig_36_1 1.0;
BA_ "initialValue" SG_ 1374 sig_41_4 0.0018377223398316216;
BA_ "sendPeriod" BO_ 820 10000;
BA_ "crcStartValue" BO_ 820 128;
BA_ "initialValue" SG_ 820 sig_0_14 -2.533722339831626E-6;
BA_ "initialValue" SG_ 820 sig_17_5 -4.622776601683793;
BA_ "initialValue" SG_ 820 sig_23_1 1.0;
BA_ "initialValue" SG_ 820 sig_22_1 1.0;
BA_ "sendPeriod" BO_ 1433 500;
BA_ "crcStartValue" BO_ 1433 73;
BA_ "initialValue" SG_ 1433 sig_3_9 270.0;
BA_ "initialValue" SG_ 1433 sig_0_3 1.0;
BA_ "initialValue" SG_ 1433 sig_15_1 1.0;
BA_ "initialValue" SG_ 1433 sig_17_15 0.057334776601683804;
BA_ "initialValue" SG_ 1433 sig_20_4 -20000.0;
BA_ "initialValue" SG_ 1433 sig_19_1 1.0;
BA_ "initialValue" SG_ 1433 sig_34_3 4.0;
BA_ "initialValue" SG_ 1433 sig_55_5 3462.2776601683795;
BA_ "sendPeriod" BO_ 1820 20;
BA_ "crcStartValue" BO_ 1820 235;
BA_ "initialValue" SG_ 1820 sig_2_16 58333.0;
BA_ "initialValue" SG_ 1820 sig_7_4 -60.0;
BA_ "sendPeriod" BO_ 1909 20;
BA_ "crcStartValue" BO_ 1909 42;
BA_ "initialValue" SG_ 1909 sig_20_17 -6320.0;
BA_ "initialValue" SG_ 1909 sig_3_9 -19.322776601683792;
BA_ "initialValue" SG_ 1909 sig_5_5 5.0;
BA_ "initialValue" SG_ 1909 sig_4_1 1.0;
BA_ "initialValue" SG_ 1909 sig_18_3 2.0;
BA_ "initialValue" SG_ 1909 sig_19_1 1.0;
BA_ "initialValue" SG_ 1909 sig_37_3 4.0;
BA_ "initialValue" SG_ 1909 sig_55_8 -583.7722339831621;
BA_ "sendPeriod" BO_ 1713 20;
BA_ "crcStartValue" BO_ 1713 103;
BA_ "initialValue" SG_ 1713 sig_33_14 1392.0;
BA_ "initialValue" SG_ 1713 sig_12_18 260469.0;
BA_ "initialValue" SG_ 1713 sig_8_4 7.837722339831626E-4;
BA_ "initialValue" SG_ 1713 sig_30_3 -1.0;
BA_ "initialValue" SG_ 1713 sig_47_3 3.0;
BA_ "initialValue" SG_ 1713 sig_55_1 1.0;
BA_ "frameSendMode" BO_ 1318 2;
BA_ "sendPeriod" BO_ 1318 500;
BA_ "eventMinDistance" BO_ 1318 100;
BA_ "crcStartValue" BO_ 1318 230;
BA_ "initialValue" SG_ 1318 sig_5_5 130.0;
BA_ "initialValue" SG_ 1318 sig_31_16 4857.8;
BA_ "initialValue" SG_ 1318 sig_22_7 20.0;
BA_ "sendPeriod" BO_ 1068 25;
BA_ "crcStartValue" BO_ 1068 11;
BA_ "initialValue" SG_ 1068 sig_7_14 0.3013722339831623;
BA_ "initialValue" SG_ 1068 sig_60_4 0.009837722339831623;
BA_ "initialValue" SG_ 1068 sig_29_12 0.00429227766016838;
BA_ "initialValue" SG_ 1068 sig_30_4 -1.0;
BA_ "initialValue" SG_ 1068 sig_51_5 5000.0;
BA_ "initialValue" SG_ 1068 sig_46_7 7.562277660168383E-5;
BA_ "initialValue" SG_ 1068 sig_50_5 -0.8;
BA_ "sendPeriod" BO_ 1670 500;
BA_ "crcStartValue" BO_ 1670 28;
BA_ "initialValue" SG_ 1670 sig_0_8 22000.0;
BA_ "initialValue" SG_ 1670 sig_21_15 22044.0;
BA_ "initialValue" SG_ 1670 sig_16_5 -1.8622776601683795;
BA_ "initialValue" SG_ 1670 sig_38_13 4136.72233983162;
BA_ "initialValue" SG_ 1670 sig_36_2 -2.0;
BA_ "initialValue" SG_ 1670 sig_51_5 15.0;
BA_ "sendPeriod" BO_ 1300 20;
BA_ "crcStartValue" BO_ 1300 53;
BA_ "initialValue" SG_ 1300 sig_0_6 -3622.7766016837923;
BA_ "initialValue" SG_ 1300 sig_27_29 -0.04859956680168381;
BA_ "initialValue" SG_ 1300 sig_17_8 14.262277660168381;
BA_ "initialValue" SG_ 1300 sig_61_6 -0.00456227766016838;
BA_ "initialValue" SG_ 1300 sig_63_2 1.0;
BA_ "sendPeriod" BO_ 1446 10000;
BA_ "crcStartValue" BO_ 1446 113;
BA_ "initialValue" SG_ 1446 sig_18_22 -0.2607609660168379;
BA_ "initialValue" SG_ 1446 sig_3_12 -5.025277660168381E-4;
BA_ "initialValue" SG_ 1446 sig_7_1 1.0;
BA_ "initialValue" SG_ 1446 sig_22_2 1.0;
BA_ "initialValue" SG_ 1446 sig_19_2 3.0;
BA_ "initialValue" SG_ 1446 sig_40_5 19.0;
BA_ "initialValue" SG_ 1446 sig_55_8 1.3500000000000003;
BA_ "frameSendMode" BO_ 144 2;
BA_ "sendPeriod" BO_ 144 1000;
BA_ "eventMinDistance" BO_ 144 500;
BA_ "crcStartValue" BO_ 144 189;
BA_ "initialValue" SG_ 144 sig_3_17 3.7626776601683796;
BA_ "initialValue" SG_ 144 sig_0_3 4.0;
BA_ "initialValue" SG_ 144 sig_20_4 -3.1622776601683795;
BA_ "initialValue" SG_ 144 sig_32_11 1.768227766016839E-5;
BA_ "initialValue" SG_ 144 sig_43_5 16.0;
BA_ "crcStartValue" BO_ 1029 153;
BA_ "initialValue" SG_ 1029 sig_7_6 -29.0;
BA_ "initialValue" SG_ 1029 sig_1_2 -2.0;
BA_ "initialValue" SG_ 1029 sig_16_33 0.06822656480168383;
BA_ "crcStartValue" BO_ 23 43;
BA_ "initialValue" SG_ 23 sig_22_7 0.32622776601683795;
BA_ "initialValue" SG_ 23 sig_6_7 8.537722339831621;
BA_ "initialValue" SG_ 23 sig_17_4 -0.04000000000000001;
BA_ "initialValue" SG_ 23 sig_16_1 1.0;
BA_ "initialValue" SG_ 23 sig_21_1 1.0;
BA_ "initialValue" SG_ 23 sig_40_22 -77.06480000000003;
BA_ "initialValue" SG_ 23 sig_62_2 2.0;
BA_ "frameSendMode" BO_ 1485 2;
BA_ "sendPeriod" BO_ 1485 10000;
BA_ "eventMinDistance" BO_ 1485 500;
BA_ "crcStartValue" BO_ 1485 154;
BA_ "initialValue" SG_ 1485 sig_11_20 22.193523398316234;
BA_ "initialValue" SG_ 1485 sig_7_12 -49372.77660168379;
BA_ "initialValue" SG_ 1485 sig_39_11 0.003450000000000002;
BA_ "initialValue" SG_ 1485 sig_42_3 -4.0;
BA_ "initialValue" SG_ 1485 sig_44_2 1.0;
BA_ "sendPeriod" BO_ 1262 10000;
BA_ "crcStartValue" BO_ 1262 20;
BA_ "initialValue" SG_ 1262 sig_7_21 1.282437766016839E-4;
BA_ "initialValue" SG_ 1262 sig_6_7 102.0;
BA_ "initialValue" SG_ 1262 sig_31_4 -0.038377223398316215;
BA_ "frameSendMode" BO_ 1512 1;
BA_ "eventMinDistance" BO_ 1512 500;
BA_ "crcStartValue" BO_ 1512 80;
BA_ "initialValue" SG_ 1512 sig_10_3 1.0;
BA_ "initialValue" SG_ 1512 sig_7_11 135.0;
BA_ "initialValue" SG_ 1512 sig_18_10 -27.622776601683793;
BA_ "initialValue" SG_ 1512 sig_23_5 1.700000000000001E-4;
BA_ "initialValue" SG_ 1512 sig_32_3 4.0;
BA_ "initialValue" SG_ 1512 sig_46_2 -2.0;
BA_ "initialValue" SG_ 1512 sig_45_2 1.0;
BA_ "sendPeriod" BO_ 912 1000;
BA_ "crcStartValue" BO_ 912 6;
BA_ "initialValue" SG_ 912 sig_23_7 -11.622776601683793;
BA_ "initialValue" SG_ 912 sig_4_13 -2.927766016837738E-4;
BA_ "initialValue" SG_ 912 sig_7_3 6.0;
BA_ "initialValue" SG_ 912 sig_32_12 3.899000000000004E-6;
BA_ "initialValue" SG_ 912 sig_47_4 9.0;
BA_ "sendPeriod" BO_ 1979 1000;
BA_ "crcStartValue" BO_ 1979 123;
BA_ "initialValue" SG_ 1979 sig_3_3 5.0;
BA_ "initialValue" SG_ 1979 sig_0_3 2.0;
BA_ "initialValue" SG_ 1979 sig_6_2 -1.0;
BA_ "initialValue" SG_ 1979 sig_18_23 0.003817484339831627;
BA_ "initialValue" SG_ 1979 sig_16_2 1.0;
BA_ "initialValue" SG_ 1979 sig_43_11 0.004772233983162122;
BA_ "initialValue" SG_ 1979 sig_42_2 -1.0;
BA_ "initialValue" SG_ 1979 sig_54_2 -2.0;
BA_ "sendPeriod" BO_ 1856 500;
BA_ "crcStartValue" BO_ 1856 15;
BA_ "initialValue" SG_ 1856 sig_20_11 0.014212277660168386;
BA_ "initialValue" SG_ 1856 sig_10_8 138.0;
BA_ "initialValue" SG_ 1856 sig_0_10 -0.19322776601683792;
BA_ "initialValue" SG_ 1856 sig_31_1 1.0;
BA_ "initialValue" SG_ 1856 sig_41_11 519.0;
BA_ "initialValue" SG_ 1856 sig_52_4 0.4837722339831621;
BA_ "frameSendMode" BO_ 74 1;
BA_ "eventMinDistance" BO_ 74 1000;
BA_ "crcStartValue" BO_ 74 2;
BA_ "initialValue" SG_ 74 sig_7_11 1873.0;
BA_ "initialValue" SG_ 74 sig_12_13 2418.0;
BA_ "crcStartValue" BO_ 1779 161;
BA_ "initialValue" SG_ 1779 sig_7_6 -6.262277660168381E-5;
BA_ "initialValue" SG_ 1779 sig_1_2 2.0;
BA_ "initialValue" SG_ 1779 sig_21_24 -110.30106601683786;
BA_ "initialValue" SG_ 1779 sig_43_10 264.0;
BA_ "initialValue" SG_ 1779 sig_63_8 -4262.27766016838;
BA_ "sendPeriod" BO_ 1385 100;
BA_ "crcStartValue" BO_ 1385 170;
BA_ "initialValue" SG_ 1385 sig_15_14 1.277400000000001E-4;
BA_ "initialValue" SG_ 1385 sig_7_1 1.0;
BA_ "initialValue" SG_ 1385 sig_3_4 -0.020000000000000004;
BA_ "initialValue" SG_ 1385 sig_17_2 1.0;
BA_ "initialValue" SG_ 1385 sig_38_15 -4694.0;
BA_ "sendPeriod" BO_ 425 10000;
BA_ "crcStartValue" BO_ 425 65;
BA_ "initialValue" SG_ 425 sig_4_18 195994.0;
BA_ "initialValue" SG_ 425 sig_24_8 28377.223398316208;
BA_ "initialValue" SG_ 425 sig_23_2 1.0;
BA_ "initialValue" SG_ 425 sig_40_8 -8.362277660168382E-4;
BA_ "sendPeriod" BO_ 1697 500;
BA_ "crcStartValue" BO_ 1697 158;
BA_ "initialValue" SG_ 1697 sig_0_4 -0.616227766016838;
BA_ "initialValue" SG_ 1697 sig_24_8 27.0;
BA_ "initialValue" SG_ 1697 sig_16_8 4737.72233983162;
BA_ "initialValue" SG_ 1697 sig_30_5 0.005262277660168381;
BA_ "initialValue" SG_ 1697 sig_40_1 1.0;
BA_ "frameSendMode" BO_ 2017 2;
BA_ "sendPeriod" BO_ 2017 10000;
BA_ "eventMinDistance" BO_ 2017 50;
BA_ "crcStartValue" BO_ 2017 105;
BA_ "initialValue" SG_ 2017 sig_6_14 -4139.0;
BA_ "initialValue" SG_ 2017 sig_0_2 2.0;
BA_ "initialValue" SG_ 2017 sig_20_12 312.0;
BA_ "initialValue" SG_ 2017 sig_46_17 -0.2817922339831624;
BA_ "initialValue" SG_ 2017 sig_40_4 -61622.77660168379;
BA_ "sendPeriod" BO_ 378 500;
BA_ "crcStartValue" BO_ 378 91;
BA_ "initialValue" SG_ 378 sig_29_8 -96.0;
BA_ "initialValue" SG_ 378 sig_4_19 5.501317660168381;
BA_ "initialValue" SG_ 378 sig_3_4 -11622.776601683792;
BA_ "initialValue" SG_ 378 sig_25_4 5.0;
BA_ "initialValue" SG_ 378 sig_24_1 1.0;
BA_ "initialValue" SG_ 378 sig_42_11 6.580000000000005E-5;
BA_ "initialValue" SG_ 378 sig_37_3 -2.0;
BA_ "initialValue" SG_ 378 sig_41_3 -4.0;
BA_ "initialValue" SG_ 378 sig_54_2 1.0;
BA_ "sendPeriod" BO_ 814 100;
BA_ "crcStartValue" BO_ 814 93;
BA_ "frameSendMode" BO_ 929 2;
BA_ "sendPeriod" BO_ 929 10000;
BA_ "eventMinDistance" BO_ 929 50;
BA_ "crcStartValue" BO_ 929 161;
BA_ "initialValue" SG_ 929 sig_2_36 -2.5613230882683786E-4;
BA_ "initialValue" SG_ 929 sig_1_2 1.0;
BA_ "initialValue" SG_ 929 sig_49_4 1.0;
BA_ "initialValue" SG_ 929 sig_55_3 1.0;
BA_ "sendPeriod" BO_ 1661 500;
BA_ "crcStartValue" BO_ 1661 126;
BA_ "initialValue" SG_ 1661 sig_7_16 43795.0;
BA_ "initialValue" SG_ 1661 sig_30_14 17.23427766016838;
BA_ "initialValue" SG_ 1661 sig_48_13 37640.0;
BA_ "initialValue" SG_ 1661 sig_47_1 1.0;
BA_ "initialValue" SG_ 1661 sig_46_1 1.0;
BA_ "initialValue" SG_ 1661 sig_62_2 1.0;
BA_ "frameSendMode" BO_ 1115 2;
BA_ "sendPeriod" BO_ 1115 1000;
BA_ "eventMinDistance" BO_ 1115 100;
BA_ "crcStartValue" BO_ 1115 11;
BA_ "initialValue" SG_ 1115 sig_19_12 3.865000000000004E-6;
BA_ "initialValue" SG_ 1115 sig_7_1 1.0;
BA_ "initialValue" SG_ 1115 sig_8_5 0.486227766016838;
BA_ "initialValue" SG_ 1115 sig_0_7 -5.262277660168381E-6;
BA_ "initialValue" SG_ 1115 sig_40_15 10547.0;
BA_ "initialValue" SG_ 1115 sig_41_7 59.0;
BA_ "sendPeriod" BO_ 1540 25;
BA_ "crcStartValue" BO_ 1540 205;
BA_ "initialValue" SG_ 1540 sig_6_13 0.7290000000000002;
BA_ "initialValue" SG_ 1540 sig_0_5 3.6622776601683795;
BA_ "initialValue" SG_ 1540 sig_23_4 3.0;
BA_ "initialValue" SG_ 1540 sig_38_13 -823.0;
BA_ "initialValue" SG_ 1540 sig_39_1 1.0;
BA_ "sendPeriod" BO_ 1831 5;
BA_ "crcStartValue" BO_ 1831 14;
BA_ "initialValue" SG_ 1831 sig_1_15 0.030395776601683792;
BA_ "initialValue" SG_ 1831 sig_28_13 461.0;
BA_ "initialValue" SG_ 1831 sig_24_3 -2.0;
BA_ "initialValue" SG_ 1831 sig_44_11 8.377223398316207;
BA_ "initialValue" SG_ 1831 sig_41_3 -2.0;
BA_ "crcStartValue" BO_ 1978 71;
BA_ "initialValue" SG_ 1978 sig_1_18 69833.0;
BA_ "initialValue" SG_ 1978 sig_7_1 1.0;
BA_ "initialValue" SG_ 1978 sig_3_4 1.0;
BA_ "initialValue" SG_ 1978 sig_25_3 4.0;
BA_ "initialValue" SG_ 1978 sig_28_4 5837.72233983162;
BA_ "initialValue" SG_ 1978 sig_41_9 6.477223398316241E-7;
BA_ "initialValue" SG_ 1978 sig_42_3 2.0;
BA_ "initialValue" SG_ 1978 sig_48_1 1.0;
BA_ "sendPeriod" BO_ 1968 10000;
BA_ "crcStartValue" BO_ 1968 43;
BA_ "initialValue" SG_ 1968 sig_5_16 3851.3776601683794;
BA_ "initialValue" SG_ 1968 sig_3_4 61622.77660168379;
BA_ "initialValue" SG_ 1968 sig_4_1 1.0;
BA_ "initialValue" SG_ 1968 sig_23_3 -3.0;
BA_ "initialValue" SG_ 1968 sig_50_9 142.0;
BA_ "initialValue" SG_ 1968 sig_35_9 107.0;
BA_ "initialValue" SG_ 1968 sig_41_2 1.0;
BA_ "initialValue" SG_ 1968 sig_40_6 0.004000000000000001;
BA_ "sendPeriod" BO_ 1795 1000;
BA_ "initialValue" SG_ 1795 sig_5_16 -2.6601000000000025E-5;
BA_ "initialValue" SG_ 1795 sig_21_5 -26.22776601683796;
BA_ "initialValue" SG_ 1795 sig_30_2 1.0;
BA_ "initialValue" SG_ 1795 sig_40_8 15.0;
BA_ "frameSendMode" BO_ 545 2;
BA_ "sendPeriod" BO_ 545 1000;
BA_ "eventMinDistance" BO_ 545 1000;
BA_ "crcStartValue" BO_ 545 232;
BA_ "initialValue" SG_ 545 sig_14_5 4.0622776601683796E-4;
BA_ "initialValue" SG_ 545 sig_15_1 1.0;
BA_ "initialValue" SG_ 545 sig_8_2 1.0;
BA_ "sendPeriod" BO_ 523 20;
BA_ "crcStartValue" BO_ 523 253;
BA_ "initialValue" SG_ 523 sig_2_19 5.6800876601683814E-6;
BA_ "initialValue" SG_ 523 sig_0_2 -2.0;
BA_ "initialValue" SG_ 523 sig_21_3 6.0;
BA_ "initialValue" SG_ 523 sig_33_12 5.104277660168381E-6;
BA_ "initialValue" SG_ 523 sig_47_9 24.6;
BA_ "frameSendMode" BO_ 1873 2;
BA_ "sendPeriod" BO_ 1873 10000;
BA_ "eventMinDistance" BO_ 1873 1000;
BA_ "crcStartValue" BO_ 1873 216;
BA_ "initialValue" SG_ 1873 sig_6_7 32.0;
BA_ "initialValue" SG_ 1873 sig_7_1 1.0;
BA_ "initialValue" SG_ 1873 sig_31_10 -490.0;
BA_ "initialValue" SG_ 1873 sig_21_8 -8.0;
BA_ "initialValue" SG_ 1873 sig_16_1 1.0;
BA_ "initialValue" SG_ 1873 sig_30_2 -1.0;
BA_ "initialValue" SG_ 1873 sig_46_6 1.6377223398316212;
BA_ "initialValue" SG_ 1873 sig_47_1 1.0;
BA_ "initialValue" SG_ 1873 sig_48_8 -55.0;
BA_ "sendPeriod" BO_ 807 10000;
BA_ "crcStartValue" BO_ 807 127;
BA_ "initialValue" SG_ 807 sig_6_1 1.0;
BA_ "initialValue" SG_ 807 sig_7_1 1.0;
BA_ "initialValue" SG_ 807 sig_20_36 0.16930266619000017;
BA_ "initialValue" SG_ 807 sig_19_4 60.0;
BA_ "initialValue" SG_ 807 sig_56_8 -0.826227766016838;
BA_ "sendPeriod" BO_ 1637 50;
BA_ "crcStartValue" BO_ 1637 236;
BA_ "initialValue" SG_ 1637 sig_23_4 -3.0;
BA_ "initialValue" SG_ 1637 sig_11_4 4.0;
BA_ "initialValue" SG_ 1637 sig_15_4 1.1000000000000007E-4;
BA_ "initialValue" SG_ 1637 sig_22_5 9.0;
BA_ "initialValue" SG_ 1637 sig_16_2 -1.0;
BA_ "initialValue" SG_ 1637 sig_31_5 9.0;
BA_ "initialValue" SG_ 1637 sig_38_7 93.0;
BA_ "frameSendMode" BO_ 1612 2;
BA_ "sendPeriod" BO_ 1612 1000;
BA_ "eventMinDistance" BO_ 1612 100;
BA_ "crcStartValue" BO_ 1612 45;
BA_ "initialValue" SG_ 1612 sig_4_15 4.35087766016838E-6;
BA_ "initialValue" SG_ 1612 sig_5_3 6.0;
BA_ "initialValue" SG_ 1612 sig_21_6 -10.0;
BA_ "initialValue" SG_ 1612 sig_40_8 9.737722339831628E-4;
BA_ "initialValue" SG_ 1612 sig_39_8 -7.237722339831627E-5;
BA_ "sendPeriod" BO_ 214 10000;
BA_ "crcStartValue" BO_ 214 251;
BA_ "initialValue" SG_ 214 sig_0_16 -0.027526000000000016;
BA_ "initialValue" SG_ 214 sig_36_19 -75017.0;
BA_ "sendPeriod" BO_ 1784 20;
BA_ "crcStartValue" BO_ 1784 40;
BA_ "initialValue" SG_ 1784 sig_6_6 7.0;
BA_ "initialValue" SG_ 1784 sig_19_10 971.0;
BA_ "initialValue" SG_ 1784 sig_23_4 0.11622776601683793;
BA_ "initialValue" SG_ 1784 sig_25_2 1.0;
BA_ "sendPeriod" BO_ 649 25;
BA_ "crcStartValue" BO_ 649 68;
BA_ "initialValue" SG_ 649 sig_12_14 8.400000000000005E-4;
BA_ "initialValue" SG_ 649 sig_10_2 -1.0;
BA_ "initialValue" SG_ 649 sig_26_14 0.0020680000000000013;
BA_ "initialValue" SG_ 649 sig_49_7 0.0036000000000000016;
